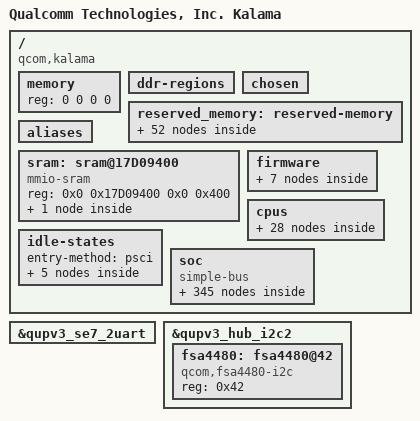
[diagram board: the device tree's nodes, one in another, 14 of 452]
#include <dt-bindings/interrupt-controller/arm-gic.h>
#include <dt-bindings/clock/qcom,camcc-kalama.h>
#include <dt-bindings/clock/qcom,dispcc-kalama.h>
#include <dt-bindings/clock/qcom,gcc-kalama.h>
#include <dt-bindings/clock/qcom,gpucc-kalama.h>
#include <dt-bindings/clock/qcom,rpmh.h>
#include <dt-bindings/clock/qcom,tcsrcc-kalama.h>
#include <dt-bindings/clock/qcom,videocc-kalama.h>
#include <dt-bindings/regulator/qcom,rpmh-regulator-levels.h>
#include <dt-bindings/interconnect/qcom,kalama.h>
#include <dt-bindings/soc/qcom,ipcc.h>
#include <dt-bindings/soc/qcom,rpmh-rsc.h>
#include <dt-bindings/interconnect/qcom,icc.h>
#include <dt-bindings/spmi/spmi.h>
#include <dt-bindings/power/qcom-aoss-qmp.h>
#include <dt-bindings/clock/qcom,aop-qmp.h>

/ {
	model = "Qualcomm Technologies, Inc. Kalama";
	compatible = "qcom,kalama";
	qcom,msm-id = <519 0x10000>;
	interrupt-parent = <&intc>;

	#address-cells = <2>;
	#size-cells = <2>;
	memory { device_type = "memory"; reg = <0 0 0 0>; };
	ddr-regions { };


	chosen: chosen {
			bootargs = "console=ttyMSM0,115200n8 loglevel=6 kpti=0 log_buf_len=256K kernel.panic_on_rcu_stall=1 service_locator.enable=1 msm_rtb.filter=0x237 rcupdate.rcu_expedited=1 rcu_nocbs=0-7 ftrace_dump_on_oops swiotlb=noforce loop.max_part=7 fw_devlink.strict=1 allow_mismatched_32bit_el0 cpufreq.default_governor=performance printk.console_no_auto_verbose=1 kasan=off sysctl.kernel.sched_pelt_multiplier=4 can.stats_timer=0 pcie_ports=compat irqaffinity=0-2 disable_dma32=on no-steal-acc cgroup.memory=nokmem,nosocket";
	};

	reserved_memory: reserved-memory { };

	aliases: aliases {
		serial0 = &qupv3_se7_2uart;
		hsuart0 = &qupv3_se14_4uart;
		sdhc2 = &sdhc_2;
		ufshc1 = &ufshc_mem; /* Embedded UFS Slot */
	};

	sram: sram@17D09400 {
		#address-cells = <2>;
		#size-cells = <2>;
		compatible = "mmio-sram";
		reg = <0x0 0x17D09400 0x0 0x400>;
		ranges = <0x0 0x0 0x0 0x17D09400 0x0 0x400>;

		cpu_scp_lpri: scmi-shmem@0 {
			compatible = "arm,scmi-shmem";
			reg = <0x0 0x0 0x0 0x400>;
		};
	};

	firmware: firmware { };

	cpus {
		#address-cells = <2>;
		#size-cells = <0>;

		CPU0: cpu@0 {
			device_type = "cpu";
			compatible = "qcom,kryo";
			reg = <0x0 0x0>;
			enable-method = "psci";
			cpu-idle-states = <&SILVER_OFF>;
			power-domains = <&CPU_PD0>;
			power-domain-names = "psci";
			cpu-release-addr = <0x0 0xE3940000>;
			qcom,freq-domain = <&cpufreq_hw 0>;
			capacity-dmips-mhz = <820>;
			dynamic-power-coefficient = <100>;
			#cooling-cells = <2>;
			next-level-cache = <&L2_0>;
			L2_0: l2-cache {
			      compatible = "arm,arch-cache";
			      cache-level = <2>;
			      next-level-cache = <&L3_0>;

				L3_0: l3-cache {
					compatible = "arm,arch-cache";
					cache-level = <3>;
				};
			};
		};

		CPU1: cpu@100 {
			device_type = "cpu";
			compatible = "qcom,kryo";
			reg = <0x0 0x100>;
			enable-method = "psci";
			cpu-idle-states = <&SILVER_OFF>;
			power-domains = <&CPU_PD1>;
			power-domain-names = "psci";
			cpu-release-addr = <0x0 0xE3940000>;
			qcom,freq-domain = <&cpufreq_hw 0>;
			capacity-dmips-mhz = <820>;
			dynamic-power-coefficient = <100>;
			#cooling-cells = <2>;
			next-level-cache = <&L2_1>;
			L2_1: l2-cache {
			      compatible = "arm,arch-cache";
			      cache-level = <2>;
			      next-level-cache = <&L3_0>;
			};
		};

		CPU2: cpu@200 {
			device_type = "cpu";
			compatible = "qcom,kryo";
			reg = <0x0 0x200>;
			enable-method = "psci";
			cpu-idle-states = <&SILVER_OFF>;
			power-domains = <&CPU_PD2>;
			power-domain-names = "psci";
			cpu-release-addr = <0x0 0xE3940000>;
			qcom,freq-domain = <&cpufreq_hw 0>;
			capacity-dmips-mhz = <820>;
			dynamic-power-coefficient = <100>;
			#cooling-cells = <2>;
			next-level-cache = <&L2_1>;
		};

		CPU3: cpu@300 {
			device_type = "cpu";
			compatible = "qcom,kryo";
			reg = <0x0 0x300>;
			enable-method = "psci";
			cpu-idle-states = <&GOLD_OFF>;
			power-domains = <&CPU_PD3>;
			power-domain-names = "psci";
			cpu-release-addr = <0x0 0xE3940000>;
			qcom,freq-domain = <&cpufreq_hw 1>;
			capacity-dmips-mhz = <1800>;
			dynamic-power-coefficient = <270>;
			#cooling-cells = <2>;
			next-level-cache = <&L2_3>;
			L2_3: l2-cache {
			      compatible = "arm,arch-cache";
			      cache-level = <2>;
			      next-level-cache = <&L3_0>;
			};
		};

		CPU4: cpu@400 {
			device_type = "cpu";
			compatible = "qcom,kryo";
			reg = <0x0 0x400>;
			enable-method = "psci";
			cpu-idle-states = <&GOLD_OFF>;
			power-domains = <&CPU_PD4>;
			power-domain-names = "psci";
			cpu-release-addr = <0x0 0xE3940000>;
			qcom,freq-domain = <&cpufreq_hw 1>;
			capacity-dmips-mhz = <1800>;
			dynamic-power-coefficient = <270>;
			#cooling-cells = <2>;
			next-level-cache = <&L2_4>;
			L2_4: l2-cache {
			      compatible = "arm,arch-cache";
			      cache-level = <2>;
			      next-level-cache = <&L3_0>;

			};
		};

		CPU5: cpu@500 {
			device_type = "cpu";
			compatible = "qcom,kryo";
			reg = <0x0 0x500>;
			enable-method = "psci";
			cpu-idle-states = <&GOLD_OFF>;
			power-domains = <&CPU_PD5>;
			power-domain-names = "psci";
			cpu-release-addr = <0x0 0xE3940000>;
			qcom,freq-domain = <&cpufreq_hw 1>;
			capacity-dmips-mhz = <1800>;
			dynamic-power-coefficient = <270>;
			#cooling-cells = <2>;
			next-level-cache = <&L2_5>;
			L2_5: l2-cache {
			      compatible = "arm,arch-cache";
			      cache-level = <2>;
			      next-level-cache = <&L3_0>;
			};
		};

		CPU6: cpu@600 {
			device_type = "cpu";
			compatible = "qcom,kryo";
			reg = <0x0 0x600>;
			enable-method = "psci";
			cpu-idle-states = <&GOLD_OFF>;
			power-domains = <&CPU_PD6>;
			power-domain-names = "psci";
			cpu-release-addr = <0x0 0xE3940000>;
			qcom,freq-domain = <&cpufreq_hw 1>;
			capacity-dmips-mhz = <1800>;
			dynamic-power-coefficient = <270>;
			#cooling-cells = <2>;
			next-level-cache = <&L2_6>;
			L2_6: l2-cache {
			      compatible = "arm,arch-cache";
			      cache-level = <2>;
			      next-level-cache = <&L3_0>;
			};
		};

		CPU7: cpu@700 {
			device_type = "cpu";
			compatible = "qcom,kryo";
			reg = <0x0 0x700>;
			enable-method = "psci";
			cpu-idle-states = <&GOLD_PLUS_OFF>;
			power-domains = <&CPU_PD7>;
			power-domain-names = "psci";
			cpu-release-addr = <0x0 0xE3940000>;
			qcom,freq-domain = <&cpufreq_hw 2>;
			capacity-dmips-mhz = <1894>;
			dynamic-power-coefficient = <588>;
			#cooling-cells = <2>;
			next-level-cache = <&L2_7>;
			L2_7: l2-cache {
			      compatible = "arm,arch-cache";
			      cache-level = <2>;
			      next-level-cache = <&L3_0>;
			};
		};

		cpu-map {
			cluster0 {
				core0 {
					cpu = <&CPU0>;
				};

				core1 {
					cpu = <&CPU1>;
				};

				core2 {
					cpu = <&CPU2>;
				};
			};

			cluster1 {
				core0 {
					cpu = <&CPU3>;
				};

				core1 {
					cpu = <&CPU4>;
				};

				core2 {
					cpu = <&CPU5>;
				};

				core3 {
					cpu = <&CPU6>;
				};
			};

			cluster2 {
				core0 {
					cpu = <&CPU7>;
				};
			};
		};
	};

	idle-states {
		entry-method = "psci";

		SILVER_OFF: silver-c4 {  /* C4 */
			compatible = "arm,idle-state";
			idle-state-name = "rail-pc";
			entry-latency-us = <550>;
			exit-latency-us = <750>;
			min-residency-us = <6700>;
			arm,psci-suspend-param = <0x40000004>;
			local-timer-stop;
		};

		GOLD_OFF: gold-c4 {  /* C4 */
			compatible = "arm,idle-state";
			idle-state-name = "rail-pc";
			entry-latency-us = <600>;
			exit-latency-us = <1300>;
			min-residency-us = <8136>;
			arm,psci-suspend-param = <0x40000004>;
			local-timer-stop;
		};

		GOLD_PLUS_OFF: gold-plus-c4 {  /* C4 */
			compatible = "arm,idle-state";
			idle-state-name = "rail-pc";
			entry-latency-us = <500>;
			exit-latency-us = <1350>;
			min-residency-us = <7480>;
			arm,psci-suspend-param = <0x40000004>;
			local-timer-stop;
		};

		CLUSTER_PWR_DN: cluster-d4 { /* D4 */
			compatible = "domain-idle-state";
			idle-state-name = "l3-off";
			entry-latency-us = <750>;
			exit-latency-us = <2350>;
			min-residency-us = <9144>;
			arm,psci-suspend-param = <0x41000044>;
		};

		APSS_OFF: cluster-e3 { /* E3 */
			compatible = "domain-idle-state";
			idle-state-name = "llcc-off";
			entry-latency-us = <2800>;
			exit-latency-us = <4400>;
			min-residency-us = <10150>;
			arm,psci-suspend-param = <0x4100c344>;
		};
	};


	soc: soc { };
};

&reserved_memory {
	#address-cells = <2>;
	#size-cells = <2>;
	ranges;

	gunyah_hyp_mem: gunyah_hyp_region@80000000 {
		no-map;
		reg = <0x0 0x80000000 0x0 0xa00000>;
	};

	cpusys_vm_mem: cpusys_vm_region@80a00000 {
		no-map;
		reg = <0x0 0x80a00000 0x0 0x400000>;
	};

	/*
	 * hyp_tags_mem & hyp_tags_reserved_mem not passed to linux
	 * as valid memory. Size of these regions varies based on
	 * bootloader policy.
	 */

	/* merged xbl_dt_log, xbl_ramdump, aop_image */
	xbl_dt_log_merged_mem: xbl_dt_log_merged@81a00000 {
		no-map;
		reg = <0x0 0x81a00000 0x0 0x260000>;
	};

	aop_cmd_db_mem: aop_cmd_db_region@81c60000 {
		compatible = "qcom,cmd-db";
		no-map;
		reg = <0x0 0x81c60000 0x0 0x20000>;
	};

	/* merged aop_config, tme_crash_dump, tme_log, uefi_log */
	aop_config_merged_mem: aop_config_merged_region@81c80000 {
		no-map;
		reg = <0x0 0x81c80000 0x0 0x74000>;
	};

	/* secdata region can be reused by apps */

	smem_mem: smem_region@81d00000 {
		no-map;
		reg = <0x0 0x81d00000 0x0 0x200000>;
	};

	adsp_mhi_mem: adsp_mhi_region@81f00000 {
		no-map;
		reg = <0x0 0x81f00000 0x0 0x20000>;
	};

	global_sync_mem: global_sync_region@82600000 {
		no-map;
		reg = <0x0 0x82600000 0x0 0x100000>;
	};

	tz_stat_mem: tz_stat_region@82700000 {
		no-map;
		reg = <0x0 0x82700000 0x0 0x100000>;
	};

	mpss_mem: mpss_region@89800000 {
		no-map;
		reg = <0x0 0x8a800000 0x0 0x10800000>;
	};

	q6_mpss_dtb_mem: q6_mpss_dtb_region@9b000000 {
		no-map;
		reg = <0x0 0x9b000000 0x0 0x80000>;
	};

	ipa_fw_mem: ipa_fw_region@9b080000 {
		no-map;
		reg = <0x0 0x9b080000 0x0 0x10000>;
	};

	ipa_gsi_mem: ipa_gsi_region@9b090000 {
		no-map;
		reg = <0x0 0x9b090000 0x0 0xa000>;
	};

	gpu_micro_code_mem: gpu_micro_code_region@9b09a000 {
		no-map;
		reg = <0x0 0x9b09a000 0x0 0x2000>;
	};

	spss_region_mem: spss_region_region@9b100000 {
		no-map;
		reg = <0x0 0x9b100000 0x0 0x180000>;
	};

	/* First part of the "SPU secure shared memory" region */
	spu_tz_shared_mem: spu_tz_shared_mem@9b280000 {
		no-map;
		reg = <0x0 0x9b280000 0x0 0x60000>;
	};

	/* Second part of the "SPU secure shared memory" region */
	spu_modem_shared_mem: spu_modem_shared_mem@9b2e0000 {
		no-map;
		reg = <0x0 0x9b2e0000 0x0 0x20000>;
	};

	camera_mem: camera_region@9b300000 {
		no-map;
		reg = <0x0 0x9b300000 0x0 0x800000>;
	};

	video_mem: video_region@9bb00000 {
		no-map;
		reg = <0x0 0x9bb00000 0x0 0x700000>;
	};

	cvp_mem: cvp_region@9c200000 {
		no-map;
		reg = <0x0 0x9c200000 0x0 0x700000>;
	};

	cdsp_mem: cdsp_region@9c900000 {
		no-map;
		reg = <0x0 0x9c900000 0x0 0x2000000>;
	};

	q6_cdsp_dtb_mem: q6_cdsp_dtb_region@9e900000 {
		no-map;
		reg = <0x0 0x9e900000 0x0 0x80000>;
	};

	q6_adsp_dtb_mem: q6_adsp_dtb_region@9e980000 {
		no-map;
		reg = <0x0 0x9e980000 0x0 0x80000>;
	};

	adspslpi_mem: adspslpi_region@9ea00000 {
		no-map;
		reg = <0x0 0x9ea00000 0x0 0x4080000>;
	};

	/* uefi region can be reused by apps */

	/* Linux kernel image is loaded at 0xa8000000 */

	mpss_dsm_mem: mpss_dsm_region@d4d00000 {
		no-map;
		reg = <0x0 0xd4d00000 0x0 0x3300000>;
	};

	/*
	 * tz_reserved_mem not passed to linux as valid memory. Size
	 * varies based on bootloader policy.
	 */

	xbl_sc_mem: xbl_sc_region@d8100000 {
		no-map;
		reg = <0x0 0xd8100000 0x0 0x40000>;
	};

	cpucp_fw_mem: cpucp_fw_region@d8140000 {
		no-map;
		reg = <0x0 0xd8140000 0x0 0x1c0000>;
	};

	qtee_mem: qtee_region@d8300000 {
		no-map;
		reg = <0x0 0xd8300000 0x0 0x500000>;
	};

	/*
	 * ta_mem & tz_tags_mem not passed to linux as valid memory. Size
	 * varies based on bootloader policy.
	 */

	hwfence_shbuf: hwfence-shmem {
		no-map;
		reg = <0x0 0xe6440000 0x0 0x2dd000>;
	};

	trust_ui_vm_mem: trust_ui_vm_region@f3800000 {
		no-map;
		reg = <0x0 0xf3800000 0x0 0x40ee000>;
	};

	trust_ui_vm_dump: trust_ui_vm_dump@0xf78ee000 {
		no-map;
		reg = <0x0 0xf78ee000 0x0 0x1000>;
	};

	trust_ui_vm_qrtr: trust_ui_vm_qrtr@0xf78ef000 {
		no-map;
		reg = <0x0 0xf78ef000 0x0 0x9000>;
	};

	trust_ui_vm_vblk0_ring: trust_ui_vm_vblk0_ring@0xf78f8000 {
		no-map;
		reg = <0x0 0xf78f8000 0x0 0x4000>;
		gunyah-label = <0x11>;					//for persist.img
	};

	trust_ui_vm_vblk1_ring: trust_ui_vm_vblk1_ring@0xf78fc000 {
		no-map;
		reg = <0x0 0xf78fc000 0x0 0x4000>;
		gunyah-label = <0x10>;					//for system.img
	};

	trust_ui_vm_swiotlb: trust_ui_vm_swiotlb@0xf7900000 {
		no-map;
		reg = <0x0 0xf7900000 0x0 0x100000>;
		gunyah-label = <0x12>;
	};

	llcc_lpi_mem: llcc_lpi_region@ff800000 {
		no-map;
		reg = <0x0 0xff800000 0x0 0x400000>;
	};

	va_md_mem: va_md_mem_region {
		compatible = "shared-dma-pool";
		alloc-ranges = <0x0 0x00000000 0x0 0xffffffff>;
		reusable;
		size = <0 0x1000000>;
	};

	sp_mem: sp_region {  /* SPSS-HLOS ION shared mem */
		compatible = "shared-dma-pool";
		alloc-ranges = <0x0 0x00000000 0x0 0xffffffff>;
		reusable;
		alignment = <0x0 0x400000>;
		size = <0x0 0x1000000>;
	};

	cdsp_eva_mem: cdsp_eva_region {
		compatible = "shared-dma-pool";
		alloc-ranges = <0x0 0x00000000 0x0 0xffffffff>;
		reusable;
		alignment = <0x0 0x400000>;
		size = <0x0 0x400000>;
	};

	adsp_mem_heap: adsp_heap_region {
		compatible = "shared-dma-pool";
		alloc-ranges = <0x0 0x00000000 0x0 0xffffffff>;
		reusable;
		alignment = <0x0 0x400000>;
		size = <0x0 0xC00000>;
	};

	user_contig_mem: user_contig_region {
		compatible = "shared-dma-pool";
		alloc-ranges = <0x0 0x00000000 0x0 0xffffffff>;
		reusable;
		alignment = <0x0 0x400000>;
		size = <0x0 0x1000000>;
	};

	qseecom_mem: qseecom_region {
		compatible = "shared-dma-pool";
		alloc-ranges = <0x0 0x00000000 0x0 0xffffffff>;
		reusable;
		alignment = <0x0 0x400000>;
		size = <0x0 0x1400000>;
	};

	cdsp_secure_heap: secure_cdsp_region { /* Secure DSP */
		compatible = "shared-dma-pool";
		alloc-ranges = <0x0 0x00000000 0x0 0xffffffff>;
		reusable;
		alignment = <0x0 0x400000>;
		size = <0x0 0x4800000>;
	};

	non_secure_display_memory: non_secure_display_region {
		compatible = "shared-dma-pool";
		reusable;
		alloc-ranges = <0x0 0x00000000 0x0 0xffffffff>;
		size = <0x0 0xa400000>;
		alignment = <0x0 0x400000>;
	};

	demura_heap_memory: demura_heap_region {
		compatible = "shared-dma-pool";
		reusable;
		alloc-ranges = <0x1 0x00000000 0xfffffffe 0xffffffff>;
		size = <0x0 0x2800000>;
		alignment = <0x0 0x400000>;
	};

	qseecom_ta_mem: qseecom_ta_region {
		compatible = "shared-dma-pool";
		alloc-ranges = <0x0 0x00000000 0x0 0xffffffff>;
		reusable;
		alignment = <0x0 0x400000>;
		size = <0x0 0x1000000>;
	};

	/* global autoconfigured region for contiguous allocations */
	system_cma: linux,cma {
		compatible = "shared-dma-pool";
		alloc-ranges = <0x0 0x00000000 0x0 0xffffffff>;
		reusable;
		alignment = <0x0 0x400000>;
		size = <0x0 0x2000000>;
		linux,cma-default;
	};

	kinfo_mem: debug_kinfo_region {
		alloc-ranges = <0x0 0x00000000 0xffffffff 0xffffffff>;
		size = <0x0 0x1000>;
		no-map;
	};

	debug_region: debug_region@ffc00000 {
		compatible = "removed-dma-pool", "qcom,debug_memory";
		no-map;
		reg = <0 0xffc00000 0 0xc0000>;
		label = "debug_mem";
	};

	last_log_region: last_log_region@ffcc0000 {
		compatible = "removed-dma-pool", "qcom,last_log_memory";
		no-map;
		reg = <0 0xffcc0000 0 0x40000>;
		label = "last_log";
		phandle = "log";
	};

	ramoops_mem: ramoops_region@ffd00000 {
		compatible = "removed-dma-pool", "ramoops";
		reg = <0 0xffd00000 0 0xc0000>;
		record-size = <0x1000>;
		console-size = <0x40000>;
		pmsg-size = <0x40000>;
		ftrace-size = <0x0>;
	};

	rdtag_store_region: rdtag_store_region@ffdc0000 {
		compatible = "removed-dma-pool", "rdtag_store_region";
		no-map;
		reg = <0 0xffdc0000 0 0x40000>;
		label = "rdtag_store_region";
	};
};

&soc {
	#address-cells = <1>;
	#size-cells = <1>;
	ranges = <0 0 0 0xffffffff>;
	compatible = "simple-bus";

	dsi_pll_codes {
	};

	psci {
		compatible = "arm,psci-1.0";
		method = "smc";

		CPU_PD0: cpu-pd0 {
			#power-domain-cells = <0>;
			power-domains = <&CLUSTER_PD>;
		};

		CPU_PD1: cpu-pd1 {
			#power-domain-cells = <0>;
			power-domains = <&CLUSTER_PD>;
		};

		CPU_PD2: cpu-pd2 {
			#power-domain-cells = <0>;
			power-domains = <&CLUSTER_PD>;
		};

		CPU_PD3: cpu-pd3 {
			#power-domain-cells = <0>;
			power-domains = <&CLUSTER_PD>;
		};

		CPU_PD4: cpu-pd4 {
			#power-domain-cells = <0>;
			power-domains = <&CLUSTER_PD>;
		};

		CPU_PD5: cpu-pd5 {
			#power-domain-cells = <0>;
			power-domains = <&CLUSTER_PD>;
		};

		CPU_PD6: cpu-pd6 {
			#power-domain-cells = <0>;
			power-domains = <&CLUSTER_PD>;
		};

		CPU_PD7: cpu-pd7 {
			#power-domain-cells = <0>;
			power-domains = <&CLUSTER_PD>;
		};

		CLUSTER_PD: cluster-pd {
			#power-domain-cells = <0>;
			domain-idle-states = <&CLUSTER_PWR_DN &APSS_OFF>;
		};
	};

	slimbam: bamdma@6C04000 {
		compatible = "qcom,bam-v1.7.0";
		qcom,controlled-remotely;
		reg = <0x6C04000 0x20000>, <0x6C8B000 0x1000>;
		reg-names = "bam", "bam_remote_mem";
		num-channels  = <31>;
		interrupts = <0 164 IRQ_TYPE_LEVEL_HIGH>;
		#dma-cells = <1>;
		qcom,ee = <1>;
		qcom,num-ees = <2>;
	};

	slim_msm: slim@6C40000 {
		compatible = "qcom,slim-ngd-v1.5.0";
		reg = <0x6C40000 0x2C000>, <0x6C8A000 0x1000>;
		reg-names = "ctrl", "slimbus_remote_mem";
		interrupts = <0 163 IRQ_TYPE_LEVEL_HIGH>;
		qcom,apps-ch-pipes = <0x0>;
		qcom,ea-pc = <0x430>;
		dmas = <&slimbam 3>, <&slimbam 4>;
		dma-names = "rx", "tx";
		#address-cells = <1>;
		#size-cells = <0>;
		status = "disabled";
	};


	intc: interrupt-controller@17100000 {
		compatible = "arm,gic-v3";
		#interrupt-cells = <3>;
		interrupt-controller;
		ranges;
		#redistributor-regions = <1>;
		redistributor-stride = <0x0 0x40000>;
		reg = <0x17100000 0x10000>,	/* GICD */
		      <0x17180000 0x200000>;	/* GICR * 8 */
		interrupts = <GIC_PPI 9 IRQ_TYPE_LEVEL_HIGH>;

		#address-cells = <1>;
		#size-cells = <1>;
		gic_its: msi-controller@17140000 {
			compatible = "arm,gic-v3-its";
			msi-controller;
			#msi-cells = <1>;
			reg = <0x17140000 0x20000>;
		};
	};

	apps_rsc: rsc@17a00000 {
		label = "apps_rsc";
		compatible = "qcom,rpmh-rsc";
		reg = <0x17a00000 0x10000>,
		      <0x17a10000 0x10000>,
		      <0x17a20000 0x10000>;
		reg-names = "drv-0", "drv-1", "drv-2";
		qcom,drv-count = <3>;
		interrupts = <GIC_SPI 3 IRQ_TYPE_LEVEL_HIGH>,
			     <GIC_SPI 4 IRQ_TYPE_LEVEL_HIGH>,
			     <GIC_SPI 5 IRQ_TYPE_LEVEL_HIGH>;
		power-domains = <&CLUSTER_PD>;

		apps_rsc_drv2: drv@2 {
			qcom,drv-id = <2>;
			qcom,tcs-offset = <0xd00>;
			channel@0 {
				qcom,tcs-config = <ACTIVE_TCS    3>,
						  <SLEEP_TCS     2>,
						  <WAKE_TCS      2>,
						  <CONTROL_TCS   0>,
						  <FAST_PATH_TCS 1>;
			};

			apps_bcm_voter: bcm_voter {
				compatible = "qcom,bcm-voter";
			};

			rpmhcc: clock-controller {
				compatible = "qcom,kalama-rpmh-clk";
				#clock-cells = <1>;
			};

			dcvs_fp: qcom,dcvs-fp {
				compatible = "qcom,dcvs-fp";
				qcom,ddr-bcm-name = "MC4";
				qcom,llcc-bcm-name = "SH5";
			};
		};
	};

	arch_timer: timer {
		compatible = "arm,armv8-timer";
		interrupts = <GIC_PPI 13 (GIC_CPU_MASK_SIMPLE(8) | IRQ_TYPE_LEVEL_LOW)>,
			     <GIC_PPI 14 (GIC_CPU_MASK_SIMPLE(8) | IRQ_TYPE_LEVEL_LOW)>,
			     <GIC_PPI 11 (GIC_CPU_MASK_SIMPLE(8) | IRQ_TYPE_LEVEL_LOW)>,
			     <GIC_PPI 12 (GIC_CPU_MASK_SIMPLE(8) | IRQ_TYPE_LEVEL_LOW)>;
		clock-frequency = <19200000>;
	};

	cam_rsc: rsc@add9000 {
		label = "cam_rsc";
		compatible = "qcom,rpmh-rsc";
		reg = <0xadd9000 0x1000>,
		      <0xadda000 0x1000>,
		      <0xaddb000 0x1000>;
		reg-names = "drv-0", "drv-1", "drv-2";
		qcom,drv-count = <3>;
		qcom,hw-channel;
		interrupts = <GIC_SPI 368 IRQ_TYPE_LEVEL_HIGH>,
			     <GIC_SPI 369 IRQ_TYPE_LEVEL_HIGH>,
			     <GIC_SPI 370 IRQ_TYPE_LEVEL_HIGH>;
		clocks = <&camcc CAM_CC_DRV_AHB_CLK>;

		cam_rsc_drv0: drv@0 {
			qcom,drv-id = <0>;
			qcom,tcs-offset = <0x520>;
			channel@0 {
				qcom,tcs-config = <ACTIVE_TCS    0>,
						  <WAKE_TCS      1>,
						  <SLEEP_TCS     1>,
						  <CONTROL_TCS   0>,
						  <FAST_PATH_TCS 0>;
			};

			channel@1 {
				qcom,tcs-config = <ACTIVE_TCS    0>,
						  <WAKE_TCS      1>,
						  <SLEEP_TCS     1>,
						  <CONTROL_TCS   0>,
						  <FAST_PATH_TCS 0>;
			};

			cam_bcm_voter0: bcm_voter {
				compatible = "qcom,bcm-voter";
			};
		};

		cam_rsc_drv1: drv@1 {
			qcom,drv-id = <1>;
			qcom,tcs-offset = <0x520>;
			channel@0 {
				qcom,tcs-config = <ACTIVE_TCS    0>,
						  <WAKE_TCS      1>,
						  <SLEEP_TCS     1>,
						  <CONTROL_TCS   0>,
						  <FAST_PATH_TCS 0>;
			};

			channel@1 {
				qcom,tcs-config = <ACTIVE_TCS    0>,
						  <WAKE_TCS      1>,
						  <SLEEP_TCS     1>,
						  <CONTROL_TCS   0>,
						  <FAST_PATH_TCS 0>;
			};

			cam_bcm_voter1: bcm_voter {
				compatible = "qcom,bcm-voter";
			};
		};

		cam_rsc_drv2: drv@2 {
			qcom,drv-id = <2>;
			qcom,tcs-offset = <0x520>;
			channel@0 {
				qcom,tcs-config = <ACTIVE_TCS    0>,
						  <WAKE_TCS      1>,
						  <SLEEP_TCS     1>,
						  <CONTROL_TCS   0>,
						  <FAST_PATH_TCS 0>;
			};

			channel@1 {
				qcom,tcs-config = <ACTIVE_TCS    0>,
						  <WAKE_TCS      1>,
						  <SLEEP_TCS     1>,
						  <CONTROL_TCS   0>,
						  <FAST_PATH_TCS 0>;
			};

			cam_bcm_voter2: bcm_voter {
				compatible = "qcom,bcm-voter";
			};
		};
	};

	disp_rsc: rsc@af20000 {
		label = "disp_rsc";
		compatible = "qcom,rpmh-rsc";
		reg = <0xaf20000 0x10000>;
		reg-names = "drv-0";
		qcom,drv-count = <1>;
		interrupts = <GIC_SPI 129 IRQ_TYPE_LEVEL_HIGH>;
		clocks = <&dispcc DISP_CC_MDSS_RSCC_AHB_CLK>;

		disp_rsc_drv0: drv@0 {
			qcom,drv-id = <0>;
			qcom,tcs-offset = <0x1c00>;
			channel@0 {
				qcom,tcs-config = <ACTIVE_TCS    0>,
						  <SLEEP_TCS     1>,
						  <WAKE_TCS      1>,
						  <CONTROL_TCS   0>,
						  <FAST_PATH_TCS 0>;
			};

			disp_bcm_voter: bcm_voter {
				compatible = "qcom,bcm-voter";
				qcom,tcs-wait = <QCOM_ICC_TAG_AMC>;
			};
		};
	};

	memtimer: timer@17420000 {
		#address-cells = <1>;
		#size-cells = <1>;
		ranges;
		compatible = "arm,armv7-timer-mem";
		reg = <0x17420000 0x1000>;
		clock-frequency = <19200000>;

		frame@17421000 {
			frame-number = <0>;
			interrupts = <GIC_SPI 8 IRQ_TYPE_LEVEL_HIGH>,
				     <GIC_SPI 6 IRQ_TYPE_LEVEL_HIGH>;
			reg = <0x17421000 0x1000>,
			      <0x17422000 0x1000>;
		};

		frame@17423000 {
			frame-number = <1>;
			interrupts = <GIC_SPI 9 IRQ_TYPE_LEVEL_HIGH>;
			reg = <0x17423000 0x1000>;
			status = "disabled";
		};

		frame@17425000 {
			frame-number = <2>;
			interrupts = <GIC_SPI 10 IRQ_TYPE_LEVEL_HIGH>;
			reg = <0x17425000 0x1000>;
			status = "disabled";
		};

		frame@17427000 {
			frame-number = <3>;
			interrupts = <GIC_SPI 11 IRQ_TYPE_LEVEL_HIGH>;
			reg = <0x17427000 0x1000>;
			status = "disabled";
		};

		frame@17429000 {
			frame-number = <4>;
			interrupts = <GIC_SPI 12 IRQ_TYPE_LEVEL_HIGH>;
			reg = <0x17429000 0x1000>;
			status = "disabled";
		};

		frame@1742b000 {
			frame-number = <5>;
			interrupts = <GIC_SPI 13 IRQ_TYPE_LEVEL_HIGH>;
			reg = <0x1742b000 0x1000>;
			status = "disabled";
		};

		frame@1742d000 {
			frame-number = <6>;
			interrupts = <GIC_SPI 14 IRQ_TYPE_LEVEL_HIGH>;
			reg = <0x1742d000 0x1000>;
			status = "disabled";
		};
	};

	rimps: qcom,rimps@17400000 {
		#address-cells = <2>;
		#size-cells = <2>;
		compatible = "qcom,rimps";
		reg =   <0x17400000 0x10>,
			<0x17d90000 0x2000>;
		#mbox-cells = <1>;
		interrupts = <GIC_SPI 62 IRQ_TYPE_LEVEL_HIGH>;
	};

	scmi: qcom,scmi {
		#address-cells = <1>;
		#size-cells = <0>;
		compatible = "arm,scmi";
		mboxes = <&rimps 0>;
		mbox-names = "tx";
		shmem = <&cpu_scp_lpri>;

		scmi_memlat: protocol@80 {
			reg = <0x80>;
			#clock-cells = <1>;
		};

		scmi_plh: protocol@81 {
			reg = <0x81>;
			#clock-cells = <1>;
		};

		scmi_pmu: protocol@86 {
			reg = <0x86>;
			#clock-cells = <1>;
		};

		scmi_c1dcvs: protocol@87 {
			reg = <0x87>;
			#clock-cells = <1>;
		};

	};

	rimps_log: qcom,rimps_log@d8140000 {
		compatible = "qcom,rimps-log";
		reg = <0xd8140000 0x10000>, <0xd8150000 0x10000>;
		mboxes = <&rimps 1>;
	};

	cpu_pmu: cpu-pmu {
		compatible = "arm,armv8-pmuv3";
		interrupts = <GIC_PPI 7 IRQ_TYPE_LEVEL_HIGH>;
	};

	dmesg-dump {
		compatible = "qcom,dmesg-dump";
		qcom,primary-vm;
		gunyah-label = <7>;
		peer-name = <2>;
		shared-buffer = <&trust_ui_vm_dump>;
	};

	clk_virt: interconnect@0 {
		compatible = "qcom,kalama-clk_virt";
		#interconnect-cells = <1>;
		qcom,bcm-voter-names = "hlos";
		qcom,bcm-voters = <&apps_bcm_voter>;
	};

	mc_virt: interconnect@1 {
		compatible = "qcom,kalama-mc_virt";
		#interconnect-cells = <1>;
		qcom,bcm-voter-names = "hlos", "disp", "cam_ife_0", "cam_ife_1", "cam_ife_2";
		qcom,bcm-voters = <&apps_bcm_voter>,
				  <&disp_bcm_voter>,
				  <&cam_bcm_voter0>,
				  <&cam_bcm_voter1>,
				  <&cam_bcm_voter2>;
	};

	config_noc: interconnect@1600000 {
		compatible = "qcom,kalama-cnoc_cfg";
		reg = <0x1600000 0x6200>;
		#interconnect-cells = <1>;
		qcom,bcm-voter-names = "hlos";
		qcom,bcm-voters = <&apps_bcm_voter>;
	};

	cnoc_main: interconnect@1500000 {
		compatible = "qcom,kalama-cnoc_main";
		reg = <0x1500000 0x13080>;
		#interconnect-cells = <1>;
		qcom,bcm-voter-names = "hlos";
		qcom,bcm-voters = <&apps_bcm_voter>;
	};

	system_noc: interconnect@1680000 {
		compatible = "qcom,kalama-system_noc";
		reg = <0x1680000 0x1D080>;
		#interconnect-cells = <1>;
		qcom,bcm-voter-names = "hlos";
		qcom,bcm-voters = <&apps_bcm_voter>;
	};

	pcie_noc: interconnect@16c0000 {
		compatible = "qcom,kalama-pcie_anoc";
		reg = <0x16c0000 0x12200>;
		#interconnect-cells = <1>;
		clocks = <&gcc GCC_AGGRE_NOC_PCIE_AXI_CLK>,
			 <&gcc GCC_CFG_NOC_PCIE_ANOC_AHB_CLK>;
		qcom,bcm-voter-names = "hlos";
		qcom,bcm-voters = <&apps_bcm_voter>;
	};

	aggre1_noc: interconnect@16e0000 {
		compatible = "qcom,kalama-aggre1_noc";
		reg = <0x16E0000 0x14400>;
		#interconnect-cells = <1>;
		clocks =
			<&gcc GCC_AGGRE_UFS_PHY_AXI_CLK>,
			<&gcc GCC_AGGRE_USB3_PRIM_AXI_CLK>;
		qcom,bcm-voter-names = "hlos";
		qcom,bcm-voters = <&apps_bcm_voter>;
	};

	aggre2_noc: interconnect@1700000 {
		compatible = "qcom,kalama-aggre2_noc";
		reg = <0x1700000 0x1E400>;
		#interconnect-cells = <1>;
		qcom,bcm-voter-names = "hlos";
		qcom,bcm-voters = <&apps_bcm_voter>;
		clocks = <&rpmhcc RPMH_IPA_CLK>;
	};

	mmss_noc: interconnect@1780000 {
		compatible = "qcom,kalama-mmss_noc";
		reg = <0x1780000 0x5B800>;
		#interconnect-cells = <1>;
		qcom,bcm-voter-names = "hlos", "disp", "cam_ife_0", "cam_ife_1", "cam_ife_2";
		qcom,bcm-voters = <&apps_bcm_voter>,
				  <&disp_bcm_voter>,
				  <&cam_bcm_voter0>,
				  <&cam_bcm_voter1>,
				  <&cam_bcm_voter2>;
	};

	gem_noc: interconnect@24100000 {
		compatible = "qcom,kalama-gem_noc";
		reg = <0x24100000 0xBB800>;
		#interconnect-cells = <1>;
		qcom,bcm-voter-names = "hlos", "disp", "cam_ife_0", "cam_ife_1", "cam_ife_2";
		qcom,bcm-voters = <&apps_bcm_voter>,
				  <&disp_bcm_voter>,
				  <&cam_bcm_voter0>,
				  <&cam_bcm_voter1>,
				  <&cam_bcm_voter2>;
	};

	nsp_noc: interconnect@320c0000 {
		compatible = "qcom,kalama-nsp_noc";
		reg = <0x320C0000 0xE080>;
		#interconnect-cells = <1>;
		qcom,bcm-voter-names = "hlos";
		qcom,bcm-voters = <&apps_bcm_voter>;
	};

	lpass_ag_noc: interconnect@7e40000 {
		compatible = "qcom,kalama-lpass_ag_noc";
		reg = <0x7e40000 0xE080>;
		#interconnect-cells = <1>;
		qcom,bcm-voter-names = "hlos";
		qcom,bcm-voters = <&apps_bcm_voter>;
	};

	lpass_lpiaon_noc: interconnect@7400000 {
		compatible = "qcom,kalama-lpass_lpiaon_noc";
		reg = <0x7400000 0x19080>;
		#interconnect-cells = <1>;
		qcom,bcm-voter-names = "hlos";
		qcom,bcm-voters = <&apps_bcm_voter>;
	};

	lpass_lpicx_noc: interconnect@7430000 {
		compatible = "qcom,kalama-lpass_lpicx_noc";
		reg = <0x7430000 0x3A200>;
		#interconnect-cells = <1>;
		qcom,bcm-voter-names = "hlos";
		qcom,bcm-voters = <&apps_bcm_voter>;
	};

	pdc: interrupt-controller@b220000 {
		compatible = "qcom,kalama-pdc", "qcom,pdc";
		reg = <0xb220000 0x30000>, <0x174000f0 0x64>;
		qcom,pdc-ranges = <0 480 94>, <94 609 31>,
				  <125 63 1>, <126 716 12>,
				  <138 251 5>;
		#interrupt-cells = <2>;
		interrupt-parent = <&intc>;
		interrupt-controller;
	};

	vendor_hooks: qcom,cpu-vendor-hooks {
		compatible = "qcom,cpu-vendor-hooks";
	};

	logbuf: qcom,logbuf-vendor-hooks {
		compatible = "qcom,logbuf-vendor-hooks";
	};

	qcom,sps {
		compatible = "qcom,msm-sps-4k";
		qcom,pipe-attr-ee;
	};

	qcom_qseecom: qseecom@c1700000 {
		compatible = "qcom,qseecom";
		memory-region = <&qseecom_mem>;
		qseecom_mem = <&qseecom_mem>;
		qseecom_ta_mem = <&qseecom_ta_mem>;
		user_contig_mem = <&user_contig_mem>;
		qcom,hlos-num-ce-hw-instances = <1>;
		qcom,hlos-ce-hw-instance = <0>;
		qcom,qsee-ce-hw-instance = <0>;
		qcom,disk-encrypt-pipe-pair = <2>;
		qcom,no-clock-support;
		qcom,appsbl-qseecom-support;
		qcom,commonlib64-loaded-by-uefi;
		qcom,qsee-reentrancy-support = <2>;
	};

	qcom_tzlog: tz-log@146AA720 {
		compatible = "qcom,tz-log";
		reg = <0x146AA720 0x3000>;
		qcom,hyplog-enabled;
		hyplog-address-offset = <0x410>;
		hyplog-size-offset = <0x414>;
	};

	qcom_cedev: qcedev@1de0000 {
		compatible = "qcom,qcedev";
		reg = <0x1de0000 0x20000>,
			<0x1dc4000 0x28000>;
		reg-names = "crypto-base","crypto-bam-base";
		interrupts = <GIC_SPI 272 IRQ_TYPE_LEVEL_HIGH>;
		qcom,bam-pipe-pair = <2>;
		qcom,offload-ops-support;
		qcom,bam-pipe-offload-cpb-hlos = <1>;
		qcom,bam-pipe-offload-hlos-cpb = <3>;
		qcom,bam-pipe-offload-hlos-hlos = <4>;
		qcom,ce-hw-instance = <0>;
		qcom,ce-device = <0>;
		qcom,ce-hw-shared;
		qcom,bam-ee = <0>;
		qcom,smmu-s1-enable;
		qcom,no-clock-support;
		interconnect-names = "data_path";
		interconnects = <&aggre2_noc MASTER_CRYPTO &mc_virt SLAVE_EBI1>;
		iommus = <&apps_smmu 0x0480 0x0>,
			<&apps_smmu 0x0481 0x0>;
		qcom,iommu-dma = "atomic";
		dma-coherent;

		qcom_cedev_ns_cb {
			compatible = "qcom,qcedev,context-bank";
			label = "ns_context";
			iommus = <&apps_smmu 0x0481 0x0>;
			dma-coherent;
		};

		qcom_cedev_s_cb {
			compatible = "qcom,qcedev,context-bank";
			label = "secure_context";
			iommus = <&apps_smmu 0x0483 0x0>;
			qcom,iommu-vmid = <0x9>;
			qcom,secure-context-bank;
			dma-coherent;
		};
	};

	qcom_rng: qrng@10c3000 {
		compatible = "qcom,msm-rng";
		reg = <0x10c3000 0x1000>;
		qcom,no-qrng-config;
		qcom,no-clock-support;
	};

	qcom,msm-imem@146aa000 {
		compatible = "qcom,msm-imem";
		reg = <0x146aa000 0x1000>;
		ranges = <0x0 0x146aa000 0x1000>;
		#address-cells = <1>;
		#size-cells = <1>;

		mem_dump_table@10 {
			compatible = "qcom,msm-imem-mem_dump_table";
			reg = <0x10 0x8>;
		};

		restart_reason@65c {
			compatible = "qcom,msm-imem-restart_reason";
			reg = <0x65c 0x4>;
		};

		dload_type@1c {
			compatible = "qcom,msm-imem-dload-type";
			reg = <0x1c 0x4>;
		};

		boot_stats@6b0 {
			compatible = "qcom,msm-imem-boot_stats";
			reg = <0x6b0 0x20>;
		};

		kaslr_offset@6d0 {
			compatible = "qcom,msm-imem-kaslr_offset";
			reg = <0x6d0 0xc>;
		};

		pil@94c {
			compatible = "qcom,pil-reloc-info";
			reg = <0x94c 0xc8>;
		};

		pil@6dc {
			compatible = "qcom,msm-imem-pil-disable-timeout";
			reg = <0x6dc 0x4>;
		};

		diag_dload@c8 {
			compatible = "qcom,msm-imem-diag-dload";
			reg = <0xc8 0xc8>;
		};
	};

	/* PIL spss node - for loading Secure Processor */
	spss_pas: remoteproc-spss@1880000 {
		compatible = "qcom,kalama-spss-pas";
		ranges;
		reg = <0x188101c 0x4>,
		      <0x1881024 0x4>,
		      <0x1881028 0x4>,
		      <0x188103c 0x4>,
		      <0x1881100 0x4>,
		      <0x1882014 0x4>;
		reg-names = "sp2soc_irq_status", "sp2soc_irq_clr", "sp2soc_irq_mask",
			    "rmb_err", "rmb_general_purpose", "rmb_err_spare2";
		interrupts = <0 352 1>;

		cx-supply = <&VDD_CX_LEVEL>;
		cx-uV-uA = <RPMH_REGULATOR_LEVEL_TURBO 100000>;

		clocks = <&rpmhcc RPMH_CXO_CLK>;
		clock-names = "xo";
		qcom,proxy-clock-names = "xo";
		status = "ok";

		memory-region = <&spss_region_mem>;
		qcom,spss-scsr-bits = <24 25>;
		qcom,extra-size = <4096>;

		interconnects = <&aggre2_noc MASTER_CRYPTO &mc_virt SLAVE_EBI1>;
		interconnect-names = "crypto_ddr";

		glink-edge {
			qcom,remote-pid = <8>;
			mboxes = <&ipcc_mproc IPCC_CLIENT_SPSS
				  IPCC_MPROC_SIGNAL_GLINK_QMP>;
			mbox-names = "spss_spss";
			interrupt-parent = <&ipcc_mproc>;
			interrupts = <IPCC_CLIENT_SPSS
				      IPCC_MPROC_SIGNAL_GLINK_QMP
				      IRQ_TYPE_EDGE_RISING>;

			reg = <0x1885008 0x8>,
			      <0x1885010 0x4>;
			reg-names = "qcom,spss-addr",
				    "qcom,spss-size";

			label = "spss";
			qcom,glink-label = "spss";
		};
	};

	qcom,spcom {
		compatible = "qcom,spcom";

		qcom,rproc-handle = <&spss_pas>;
		qcom,boot-enabled;
		/* predefined channels, remote side is server */
		qcom,spcom-ch-names = "sp_kernel", "sp_ssr";
		/* sp2soc rmb shared register physical address and bmsk */
		qcom,spcom-sp2soc-rmb-reg-addr = <0x01881020>;
		qcom,spcom-sp2soc-rmb-initdone-bit = <24>;
		qcom,spcom-sp2soc-rmb-pbldone-bit = <25>;
		/* soc2sp rmb shared register physical address */
		qcom,spcom-soc2sp-rmb-reg-addr = <0x01881030>;
		qcom,spcom-soc2sp-rmb-sp-ssr-bit = <0>;
		status = "ok";
	};

	spss_utils: qcom,spss_utils {
		compatible = "qcom,spss-utils";
		/* spss fuses physical address */
		qcom,rproc-handle = <&spss_pas>;
		qcom,spss-fuse1-addr = <0x221C8214>;
		qcom,spss-fuse1-bit = <8>;
		qcom,spss-fuse2-addr = <0x221C8214>;
		qcom,spss-fuse2-bit = <7>;
		qcom,spss-dev-firmware-name  = "spss1d.mdt";  /* 8 chars max */
		qcom,spss-test-firmware-name = "spss1t.mdt";  /* 8 chars max */
		qcom,spss-prod-firmware-name = "spss1p.mdt";  /* 8 chars max */
		qcom,spss-debug-reg-addr = <0x01886020>;
		qcom,spss-debug-reg-addr1 = <0x01888020>;
		qcom,spss-debug-reg-addr3 = <0x0188C020>;
		qcom,spss-emul-type-reg-addr = <0x01fc8004>;
		pil-mem = <&spss_region_mem>;
		qcom,pil-size = <0x0F0000>; // padding to 960KB
		status = "ok";
	};

	qcom,msm-rtb {
		compatible = "qcom,msm-rtb";
		qcom,rtb-size = <0x100000>;
	};

	tlmm: pinctrl@f000000 {
		compatible = "qcom,kalama-pinctrl";
		reg = <0x0F000000 0x1000000>;
		interrupts = <GIC_SPI 208 IRQ_TYPE_LEVEL_HIGH>;
		gpio-controller;
		#gpio-cells = <2>;
		interrupt-controller;
		#interrupt-cells = <2>;
		wakeup-parent = <&pdc>;
		qcom,gpios-reserved = <32 33 34 35 36 37 38 39>;
	};

	dload_mode {
		compatible = "qcom,dload-mode";
	};

	microdump_modem {
		compatible = "qcom,microdump_modem";
	 };

	mini_dump_mode {
		compatible = "qcom,minidump";
		status = "ok";
	};

	va_mini_dump {
		compatible = "qcom,va-minidump";
		memory-region = <&va_md_mem>;
		status = "ok";
	};

	gic-interrupt-router {
		compatible = "qcom,gic-intr-routing";
		/* keep silver core only to avoid wakeup of gold cores */
		qcom,gic-class0-cpus = <0 1 2>;
		/* keep gold and gold+ cores in class1 */
		qcom,gic-class1-cpus = <3 4 5 6 7>;
	};

	qcom,secure-buffer {
		compatible = "qcom,secure-buffer";
		qcom,vmid-cp-camera-preview-ro;
	};

	qcom,mem-buf {
		compatible = "qcom,mem-buf";
		qcom,mem-buf-capabilities = "supplier";
		qcom,vmid = <3>;
	};

	qcom,mem-buf-msgq {
		compatible = "qcom,mem-buf-msgq";
	};

	qcom,memshare {
		compatible = "qcom,memshare";

		qcom,client_1 {
			compatible = "qcom,memshare-peripheral";
			qcom,peripheral-size = <0x0>;
			qcom,client-id = <0>;
			qcom,allocate-boot-time;
			label = "modem";
		};

		qcom,client_2 {
			compatible = "qcom,memshare-peripheral";
			qcom,peripheral-size = <0x0>;
			qcom,client-id = <2>;
			label = "modem";
		};

		qcom,client_3 {
			compatible = "qcom,memshare-peripheral";
			qcom,peripheral-size = <0x500000>;
			qcom,client-id = <1>;
			qcom,allocate-on-request;
			label = "modem";
		};
	};

	clocks {
		xo_board: xo_board {
			compatible = "fixed-clock";
			clock-frequency = <76800000>;
			clock-output-names = "xo_board";
			#clock-cells = <0>;
		};

		sleep_clk: sleep_clk {
			compatible = "fixed-clock";
			clock-frequency = <32000>;
			clock-output-names = "sleep_clk";
			#clock-cells = <0>;
		};
	};

	camcc: clock-controller@ade0000 {
		compatible = "qcom,kalama-camcc", "syscon";
		reg = <0xade0000 0x20000>;
		reg-name = "cc_base";
		vdd_mm-supply = <&VDD_MM_LEVEL>;
		vdd_mxa-supply = <&VDD_MXA_LEVEL>;
		vdd_mxc-supply = <&VDD_MXC_LEVEL>;
		clocks = <&rpmhcc RPMH_CXO_CLK>,
			 <&rpmhcc RPMH_CXO_CLK_A>,
			 <&sleep_clk>,
			 <&gcc GCC_CAMERA_AHB_CLK>;
		clock-names = "bi_tcxo",
			      "bi_tcxo_ao",
			      "sleep_clk",
			      "iface";
		#clock-cells = <1>;
		#reset-cells = <1>;
	};

	cpuss-sleep-stats@17800054 {
	      compatible = "qcom,cpuss-sleep-stats";
	      reg = <0x17800054 0x4>, <0x17810054 0x4>, <0x17820054 0x4>,
		    <0x17830054 0x4>, <0x17840054 0x4>, <0x17850054 0x4>,
		    <0x17860054 0x4>, <0x17870054 0x4>, <0x178a0098 0x4>,
		    <0x178c0000 0x10000>;
	      reg-names = "seq_lpm_cntr_cfg_cpu0", "seq_lpm_cntr_cfg_cpu1",
			  "seq_lpm_cntr_cfg_cpu2", "seq_lpm_cntr_cfg_cpu3",
			  "seq_lpm_cntr_cfg_cpu4", "seq_lpm_cntr_cfg_cpu5",
			  "seq_lpm_cntr_cfg_cpu6", "seq_lpm_cntr_cfg_cpu7",
			  "l3_seq_lpm_cntr_cfg", "apss_seq_mem_base";
	      num-cpus = <8>;
	};

	dispcc: clock-controller@af00000 {
		compatible = "qcom,kalama-dispcc", "syscon";
		reg = <0xaf00000 0x20000>;
		reg-name = "cc_base";
		vdd_mm-supply = <&VDD_MM_LEVEL>;
		vdd_mxa-supply = <&VDD_MXA_LEVEL>;
		clocks = <&rpmhcc RPMH_CXO_CLK>,
			 <&sleep_clk>,
			 <&gcc GCC_DISP_AHB_CLK>;
		clock-names = "bi_tcxo",
			      "sleep_clk",
			      "iface";
		#clock-cells = <1>;
		#reset-cells = <1>;
	};

	pcie_0_pipe_clk: pcie_0_pipe_clk {
		compatible = "fixed-clock";
		clock-frequency = <1000>;
		clock-output-names = "pcie_0_pipe_clk";
		#clock-cells = <0>;
	};

	pcie_1_phy_aux_clk: pcie_1_phy_aux_clk {
		compatible = "fixed-clock";
		clock-frequency = <1000>;
		clock-output-names = "pcie_1_phy_aux_clk";
		#clock-cells = <0>;
	};

	pcie_1_pipe_clk: pcie_1_pipe_clk {
		compatible = "fixed-clock";
		clock-frequency = <1000>;
		clock-output-names = "pcie_1_pipe_clk";
		#clock-cells = <0>;
	};

	ufs_phy_rx_symbol_0_clk: ufs_phy_rx_symbol_0_clk {
		compatible = "fixed-clock";
		clock-frequency = <1000>;
		clock-output-names = "ufs_phy_rx_symbol_0_clk";
		#clock-cells = <0>;
	};

	ufs_phy_rx_symbol_1_clk: ufs_phy_rx_symbol_1_clk {
		compatible = "fixed-clock";
		clock-frequency = <1000>;
		clock-output-names = "ufs_phy_rx_symbol_1_clk";
		#clock-cells = <0>;
	};

	ufs_phy_tx_symbol_0_clk: ufs_phy_tx_symbol_0_clk {
		compatible = "fixed-clock";
		clock-frequency = <1000>;
		clock-output-names = "ufs_phy_tx_symbol_0_clk";
		#clock-cells = <0>;
	};

	usb3_phy_wrapper_gcc_usb30_pipe_clk: usb3_phy_wrapper_gcc_usb30_pipe_clk {
		compatible = "fixed-clock";
		clock-frequency = <1000>;
		clock-output-names = "usb3_phy_wrapper_gcc_usb30_pipe_clk";
		#clock-cells = <0>;
	};

	gcc: clock-controller@100000 {
		compatible = "qcom,kalama-gcc", "syscon";
		reg = <0x100000 0x1f4200>;
		reg-name = "cc_base";
		vdd_cx-supply = <&VDD_CX_LEVEL>;
		vdd_mxa-supply = <&VDD_MXA_LEVEL>;
		clocks = <&rpmhcc RPMH_CXO_CLK>,
			 <&pcie_0_pipe_clk>,
			 <&pcie_1_phy_aux_clk>,
			 <&pcie_1_pipe_clk>,
			 <&sleep_clk>,
			 <&ufs_phy_rx_symbol_0_clk>,
			 <&ufs_phy_rx_symbol_1_clk>,
			 <&ufs_phy_tx_symbol_0_clk>,
			 <&usb3_phy_wrapper_gcc_usb30_pipe_clk>;
		clock-names = "bi_tcxo",
			      "pcie_0_pipe_clk",
			      "pcie_1_phy_aux_clk",
			      "pcie_1_pipe_clk",
			      "sleep_clk",
			      "ufs_phy_rx_symbol_0_clk",
			      "ufs_phy_rx_symbol_1_clk",
			      "ufs_phy_tx_symbol_0_clk",
			      "usb3_phy_wrapper_gcc_usb30_pipe_clk";
		#clock-cells = <1>;
		#reset-cells = <1>;
	};

	gpucc: clock-controller@3d90000 {
		compatible = "qcom,kalama-gpucc", "syscon";
		reg = <0x3d90000 0xa000>;
		reg-name = "cc_base";
		vdd_cx-supply = <&VDD_CX_LEVEL>;
		vdd_mx-supply = <&VDD_MXA_LEVEL>;
		vdd_mxc-supply = <&VDD_MXC_LEVEL>;
		clocks = <&rpmhcc RPMH_CXO_CLK>,
			 <&gcc GCC_GPU_GPLL0_CLK_SRC>,
			 <&gcc GCC_GPU_GPLL0_DIV_CLK_SRC>;
		clock-names = "bi_tcxo",
			      "gpll0_out_main",
			      "gpll0_out_main_div";
		#clock-cells = <1>;
		#reset-cells = <1>;
	};

	tcsrcc: clock-controller@1fc0000 {
		compatible = "qcom,kalama-tcsrcc", "syscon";
		reg = <0x1fc0000 0x30000>;
		reg-name = "cc_base";
		#clock-cells = <1>;
		#reset-cells = <1>;
	};

	videocc: clock-controller@aaf0000 {
		compatible = "qcom,kalama-videocc", "syscon";
		reg = <0xaaf0000 0x10000>;
		reg-name = "cc_base";
		vdd_mm-supply = <&VDD_MM_LEVEL>;
		vdd_mxc-supply = <&VDD_MXC_LEVEL>;
		clocks = <&rpmhcc RPMH_CXO_CLK>,
			 <&rpmhcc RPMH_CXO_CLK_A>,
			 <&sleep_clk>,
			 <&gcc GCC_VIDEO_AHB_CLK>;
		clock-names = "bi_tcxo",
			      "bi_tcxo_ao",
			      "sleep_clk",
			      "iface";
		#clock-cells = <1>;
		#reset-cells = <1>;
	};

	apsscc: syscon@17A80000 {
		compatible = "syscon";
		reg = <0x17A80000 0x21000>;
	};

	mccc: syscon@240ba000 {
		compatible = "syscon";
		reg = <0x240ba000 0x54>;
	};

	debugcc: clock-controller@0 {
		compatible = "qcom,kalama-debugcc";
		qcom,apsscc = <&apsscc>;
		qcom,camcc = <&camcc>;
		qcom,dispcc = <&dispcc>;
		qcom,gcc = <&gcc>;
		qcom,gpucc = <&gpucc>;
		qcom,tcsrcc = <&tcsrcc>;
		qcom,videocc = <&videocc>;
		qcom,mccc = <&mccc>;
		clocks = <&rpmhcc RPMH_CXO_CLK>,
			 <&camcc 0>,
			 <&dispcc 0>,
			 <&gcc 0>,
			 <&gpucc 0>,
			 <&tcsrcc 0>,
			 <&videocc 0>;
		clock-names = "xo_clk_src",
			      "camcc",
			      "dispcc",
			      "gcc",
			      "gpucc",
			      "tcsrcc",
			      "videocc";
		#clock-cells = <1>;
	};

	cpufreq_hw: qcom,cpufreq-hw {
		compatible = "qcom,cpufreq-epss";
		reg = <0x17D91000 0x1000>,
		      <0x17D92000 0x1000>,
		      <0x17D93000 0x1000>;
		reg-names = "freq-domain0",
			    "freq-domain1",
			    "freq-domain2";
		clocks = <&rpmhcc RPMH_CXO_CLK>, <&gcc GCC_GPLL0>;
		clock-names = "xo", "alternate";
		interrupts = <GIC_SPI 30 IRQ_TYPE_LEVEL_HIGH>,
			     <GIC_SPI 31 IRQ_TYPE_LEVEL_HIGH>,
			     <GIC_SPI 19 IRQ_TYPE_LEVEL_HIGH>;
		interrupt-names = "dcvsh0_int",
				  "dcvsh1_int",
				  "dcvsh2_int";
		#freq-domain-cells = <1>;
	};

	qcom,cpufreq-hw-debug {
		compatible = "qcom,cpufreq-hw-epss-debug";
		qcom,freq-hw-domain = <&cpufreq_hw 0>,
				      <&cpufreq_hw 1>,
				      <&cpufreq_hw 2>;
	};

	/* CAM_CC GDSCs */
	cam_cc_bps_gdsc: qcom,gdsc@adf0004 {
		compatible = "qcom,gdsc";
		reg = <0xadf0004 0x4>;
		regulator-name = "cam_cc_bps_gdsc";
		clock-names = "ahb_clk";
		clocks = <&gcc GCC_CAMERA_AHB_CLK>;
		parent-supply = <&VDD_MM_MXC_VOTER_LEVEL>;
		qcom,gds-timeout = <1500>;
		qcom,support-hw-trigger;
		qcom,retain-regs;
		qcom,support-cfg-gdscr;
	};

	cam_cc_ife_0_gdsc: qcom,gdsc@adf1004 {
		compatible = "qcom,gdsc";
		reg = <0xadf1004 0x4>;
		regulator-name = "cam_cc_ife_0_gdsc";
		clock-names = "ahb_clk";
		clocks = <&gcc GCC_CAMERA_AHB_CLK>;
		parent-supply = <&VDD_MM_MXC_VOTER_LEVEL>;
		qcom,gds-timeout = <1500>;
		qcom,retain-regs;
		qcom,support-cfg-gdscr;
	};

	cam_cc_ife_1_gdsc: qcom,gdsc@adf2004 {
		compatible = "qcom,gdsc";
		reg = <0xadf2004 0x4>;
		regulator-name = "cam_cc_ife_1_gdsc";
		clock-names = "ahb_clk";
		clocks = <&gcc GCC_CAMERA_AHB_CLK>;
		parent-supply = <&VDD_MM_MXC_VOTER_LEVEL>;
		qcom,gds-timeout = <1500>;
		qcom,retain-regs;
		qcom,support-cfg-gdscr;
	};

	cam_cc_ife_2_gdsc: qcom,gdsc@adf2294 {
		compatible = "qcom,gdsc";
		reg = <0xadf2294 0x4>;
		regulator-name = "cam_cc_ife_2_gdsc";
		clock-names = "ahb_clk";
		clocks = <&gcc GCC_CAMERA_AHB_CLK>;
		parent-supply = <&VDD_MM_MXC_VOTER_LEVEL>;
		qcom,gds-timeout = <1500>;
		qcom,retain-regs;
		qcom,support-cfg-gdscr;
	};

	cam_cc_ipe_0_gdsc: qcom,gdsc@adf03b8 {
		compatible = "qcom,gdsc";
		reg = <0xadf03b8 0x4>;
		regulator-name = "cam_cc_ipe_0_gdsc";
		clock-names = "ahb_clk";
		clocks = <&gcc GCC_CAMERA_AHB_CLK>;
		parent-supply = <&VDD_MM_MXC_VOTER_LEVEL>;
		qcom,gds-timeout = <1500>;
		qcom,support-hw-trigger;
		qcom,retain-regs;
		qcom,support-cfg-gdscr;
	};

	cam_cc_sbi_gdsc: qcom,gdsc@adf052c {
		compatible = "qcom,gdsc";
		reg = <0xadf052c 0x4>;
		regulator-name = "cam_cc_sbi_gdsc";
		clock-names = "ahb_clk";
		clocks = <&gcc GCC_CAMERA_AHB_CLK>;
		parent-supply = <&VDD_MM_MXC_VOTER_LEVEL>;
		qcom,gds-timeout = <1500>;
		qcom,retain-regs;
		qcom,support-cfg-gdscr;
	};

	cam_cc_sfe_0_gdsc: qcom,gdsc@adf3280 {
		compatible = "qcom,gdsc";
		reg = <0xadf3280 0x4>;
		regulator-name = "cam_cc_sfe_0_gdsc";
		clock-names = "ahb_clk";
		clocks = <&gcc GCC_CAMERA_AHB_CLK>;
		parent-supply = <&VDD_MM_MXC_VOTER_LEVEL>;
		qcom,gds-timeout = <1500>;
		qcom,retain-regs;
		qcom,support-cfg-gdscr;
	};

	cam_cc_sfe_1_gdsc: qcom,gdsc@adf33e0 {
		compatible = "qcom,gdsc";
		reg = <0xadf33e0 0x4>;
		regulator-name = "cam_cc_sfe_1_gdsc";
		clock-names = "ahb_clk";
		clocks = <&gcc GCC_CAMERA_AHB_CLK>;
		parent-supply = <&VDD_MM_MXC_VOTER_LEVEL>;
		qcom,gds-timeout = <1500>;
		qcom,retain-regs;
		qcom,support-cfg-gdscr;
	};

	cam_cc_titan_top_gdsc: qcom,gdsc@adf4058 {
		compatible = "qcom,gdsc";
		reg = <0xadf4058 0x4>;
		regulator-name = "cam_cc_titan_top_gdsc";
		clock-names = "ahb_clk";
		clocks = <&gcc GCC_CAMERA_AHB_CLK>;
		parent-supply = <&VDD_MM_MXC_VOTER_LEVEL>;
		proxy-supply = <&cam_cc_titan_top_gdsc>;
		interconnects = <&mmss_noc MASTER_CAMNOC_HF &mmss_noc SLAVE_MNOC_HF_MEM_NOC>;
		interconnect-names = "mmnoc";
		qcom,gds-timeout = <1500>;
		qcom,proxy-consumer-enable;
		qcom,retain-regs;
		qcom,support-cfg-gdscr;
	};

	/* DISP_CC GDSCs */
	disp_cc_mdss_core_gdsc: qcom,gdsc@af09000 {
		compatible = "qcom,gdsc";
		reg = <0xaf09000 0x4>;
		regulator-name = "disp_cc_mdss_core_gdsc";
		clock-names = "ahb_clk";
		clocks = <&gcc GCC_DISP_AHB_CLK>;
		parent-supply = <&VDD_MM_LEVEL>;
		proxy-supply = <&disp_cc_mdss_core_gdsc>;
		qcom,gds-timeout = <1500>;
		qcom,proxy-consumer-enable;
		qcom,support-hw-trigger;
		qcom,retain-regs;
		qcom,support-cfg-gdscr;
	};

	disp_cc_mdss_core_int2_gdsc: qcom,gdsc@af0b000 {
		compatible = "qcom,gdsc";
		reg = <0xaf0b000 0x4>;
		regulator-name = "disp_cc_mdss_core_int2_gdsc";
		clock-names = "ahb_clk";
		clocks = <&gcc GCC_DISP_AHB_CLK>;
		parent-supply = <&VDD_MM_LEVEL>;
		qcom,gds-timeout = <1500>;
		qcom,support-hw-trigger;
		qcom,retain-regs;
		qcom,support-cfg-gdscr;
	};

	gcc_apcs_gdsc_vote_ctrl: syscon@152020{
		compatible = "syscon";
		reg = <0x152020 0x4>;
	};

	/* GCC GDSCs */
	gcc_pcie_0_gdsc: qcom,gdsc@16b004 {
		compatible = "qcom,gdsc";
		reg = <0x16b004 0x4>;
		regulator-name = "gcc_pcie_0_gdsc";
		parent-supply = <&VDD_CX_LEVEL>;
		clocks = <&gcc 0>;
		qcom,gds-timeout = <1500>;
		qcom,retain-regs;
		qcom,no-status-check-on-disable;
		qcom,collapse-vote = <&gcc_apcs_gdsc_vote_ctrl 0>;
		qcom,support-cfg-gdscr;
	};

	gcc_pcie_0_phy_gdsc: qcom,gdsc@16c000 {
		compatible = "qcom,gdsc";
		reg = <0x16c000 0x4>;
		regulator-name = "gcc_pcie_0_phy_gdsc";
		parent-supply = <&VDD_MXA_LEVEL>;
		clocks = <&gcc 0>;
		qcom,gds-timeout = <1500>;
		qcom,retain-regs;
		qcom,no-status-check-on-disable;
		qcom,collapse-vote = <&gcc_apcs_gdsc_vote_ctrl 3>;
		qcom,support-cfg-gdscr;
	};

	gcc_pcie_1_gdsc: qcom,gdsc@18d004 {
		compatible = "qcom,gdsc";
		reg = <0x18d004 0x4>;
		regulator-name = "gcc_pcie_1_gdsc";
		parent-supply = <&VDD_CX_LEVEL>;
		clocks = <&gcc 0>;
		qcom,gds-timeout = <1500>;
		qcom,retain-regs;
		qcom,no-status-check-on-disable;
		qcom,collapse-vote = <&gcc_apcs_gdsc_vote_ctrl 1>;
		qcom,support-cfg-gdscr;
	};

	gcc_pcie_1_phy_gdsc: qcom,gdsc@18e000 {
		compatible = "qcom,gdsc";
		reg = <0x18e000 0x4>;
		regulator-name = "gcc_pcie_1_phy_gdsc";
		parent-supply = <&VDD_MXA_LEVEL>;
		clocks = <&gcc 0>;
		qcom,gds-timeout = <1500>;
		qcom,retain-regs;
		qcom,no-status-check-on-disable;
		qcom,collapse-vote = <&gcc_apcs_gdsc_vote_ctrl 4>;
		qcom,support-cfg-gdscr;
	};

	gcc_ufs_mem_phy_gdsc: qcom,gdsc@19e000 {
		compatible = "qcom,gdsc";
		reg = <0x19e000 0x4>;
		regulator-name = "gcc_ufs_mem_phy_gdsc";
		clocks = <&gcc 0>;
		qcom,gds-timeout = <1500>;
		parent-supply = <&VDD_MXA_LEVEL>;
		qcom,retain-regs;
		qcom,support-cfg-gdscr;
	};

	gcc_ufs_phy_gdsc: qcom,gdsc@177004 {
		compatible = "qcom,gdsc";
		reg = <0x177004 0x4>;
		regulator-name = "gcc_ufs_phy_gdsc";
		parent-supply = <&VDD_CX_LEVEL>;
		proxy-supply = <&gcc_ufs_phy_gdsc>;
		clocks = <&gcc 0>;
		qcom,gds-timeout = <1500>;
		qcom,proxy-consumer-enable;
		qcom,retain-regs;
		qcom,support-cfg-gdscr;
	};

	gcc_usb30_prim_gdsc: qcom,gdsc@139004 {
		compatible = "qcom,gdsc";
		reg = <0x139004 0x4>;
		regulator-name = "gcc_usb30_prim_gdsc";
		proxy-supply = <&gcc_usb30_prim_gdsc>;
		clocks = <&gcc 0>;
		qcom,gds-timeout = <1500>;
		qcom,proxy-consumer-enable;
		qcom,retain-regs;
		qcom,support-cfg-gdscr;
	};

	gcc_usb3_phy_gdsc: qcom,gdsc@150018 {
		compatible = "qcom,gdsc";
		reg = <0x150018 0x4>;
		regulator-name = "gcc_usb3_phy_gdsc";
		clocks = <&gcc 0>;
		qcom,gds-timeout = <1500>;
		parent-supply = <&VDD_MXA_LEVEL>;
		qcom,proxy-consumer-enable;
		qcom,retain-regs;
		qcom,support-cfg-gdscr;
	};

	/* GPU_CC GDSCs */
	gpu_cc_cx_gdsc_hw_ctrl: syscon@3d9953c {
		compatible = "syscon";
		reg = <0x3d9953c 0x4>;
	};

	gpu_cc_cx_gdsc: qcom,gdsc@3d99108 {
		compatible = "qcom,gdsc";
		reg = <0x3d99108 0x4>;
		regulator-name = "gpu_cc_cx_gdsc";
		parent-supply = <&VDD_CX_LEVEL>;
		hw-ctrl-addr = <&gpu_cc_cx_gdsc_hw_ctrl>;
		qcom,no-status-check-on-disable;
		qcom,clk-dis-wait-val = <8>;
		qcom,gds-timeout = <1500>;
		qcom,retain-regs;
	};

	gpu_cc_gx_domain_addr: syscon@3d99504 {
		compatible = "syscon";
		reg = <0x3d99504 0x4>;
	};

	gpu_cc_gx_sw_reset: syscon@3d99058 {
		compatible = "syscon";
		reg = <0x3d99058 0x4>;
	};

	gpu_cc_gx_acd_reset: syscon@3d99358 {
		compatible = "syscon";
		reg = <0x3d99358 0x4>;
	};

	gpu_cc_gx_acd_iroot_reset: syscon@3d9958c {
		compatible = "syscon";
		reg = <0x3d9958c 0x4>;
	};

	gpu_cc_gx_gdsc: qcom,gdsc@3d9905c {
		compatible = "qcom,gdsc";
		reg = <0x3d9905c 0x4>;
		regulator-name = "gpu_cc_gx_gdsc";
		domain-addr = <&gpu_cc_gx_domain_addr>;
		sw-reset = <&gpu_cc_gx_sw_reset>,
			   <&gpu_cc_gx_acd_reset>,
			   <&gpu_cc_gx_acd_iroot_reset>;
		parent-supply = <&VDD_GFX_MXC_VOTER_LEVEL>;
		qcom,reset-aon-logic;
		qcom,gds-timeout = <1500>;
		qcom,retain-regs;
		qcom,support-cfg-gdscr;
	};

	/* VIDEO_CC GDSCs */
	video_cc_mvs0_gdsc: qcom,gdsc@abf80a4 {
		compatible = "qcom,gdsc";
		reg = <0xabf80a4 0x4>;
		regulator-name = "video_cc_mvs0_gdsc";
		parent-supply = <&video_cc_mvs0c_gdsc>;
		clock-names = "ahb_clk";
		clocks = <&gcc GCC_VIDEO_AHB_CLK>;
		qcom,gds-timeout = <1500>;
		qcom,support-hw-trigger;
		qcom,retain-regs;
		qcom,support-cfg-gdscr;
	};

	video_cc_mvs0c_gdsc: qcom,gdsc@abf804c {
		compatible = "qcom,gdsc";
		reg = <0xabf804c 0x4>;
		regulator-name = "video_cc_mvs0c_gdsc";
		clock-names = "ahb_clk";
		clocks = <&gcc GCC_VIDEO_AHB_CLK>;
		parent-supply = <&VDD_MM_MXC_VOTER_LEVEL>;
		qcom,gds-timeout = <1500>;
		qcom,retain-regs;
		qcom,support-cfg-gdscr;
	};

	video_cc_mvs1_gdsc: qcom,gdsc@abf80cc {
		compatible = "qcom,gdsc";
		reg = <0xabf80cc 0x4>;
		regulator-name = "video_cc_mvs1_gdsc";
		parent-supply = <&video_cc_mvs1c_gdsc>;
		clock-names = "ahb_clk";
		clocks = <&gcc GCC_VIDEO_AHB_CLK>;
		qcom,gds-timeout = <1500>;
		qcom,support-hw-trigger;
		qcom,retain-regs;
		qcom,support-cfg-gdscr;
	};

	video_cc_mvs1c_gdsc: qcom,gdsc@abf8078 {
		compatible = "qcom,gdsc";
		reg = <0xabf8078 0x4>;
		regulator-name = "video_cc_mvs1c_gdsc";
		parent-supply = <&VDD_MM_MXC_VOTER_LEVEL>;
		clock-names = "ahb_clk";
		clocks = <&gcc GCC_VIDEO_AHB_CLK>;
		qcom,gds-timeout = <1500>;
		qcom,retain-regs;
		qcom,support-cfg-gdscr;
	};

	sdhc2_opp_table: sdhc2-opp-table {
		compatible = "operating-points-v2";

		opp-100000000 {
			opp-hz = /bits/ 64 <100000000>;
			opp-peak-kBps = <160000 100000>;
			opp-avg-kBps = <50000 0>;
		};

		opp-202000000 {
			opp-hz = /bits/ 64 <202000000>;
			opp-peak-kBps = <200000 120000>;
			opp-avg-kBps = <104000 0>;
		};
	};

	sdhc_2: sdhci@8804000 {
		status = "disabled";

		compatible = "qcom,sdhci-msm-v5";
		reg = <0x08804000 0x1000>;
		reg-names = "hc_mem";

		interrupts = <GIC_SPI 207 IRQ_TYPE_LEVEL_HIGH>,
				<GIC_SPI 223 IRQ_TYPE_LEVEL_HIGH>;
		interrupt-names = "hc_irq", "pwr_irq";

		bus-width = <4>;
		no-sdio;
		no-mmc;
		qcom,restore-after-cx-collapse;
		qcom,uses_level_shifter;
		qcom,dll_lock_bist_fail_wa;

		clocks = <&gcc GCC_SDCC2_AHB_CLK>,
			<&gcc GCC_SDCC2_APPS_CLK>;
		clock-names = "iface", "core";

		/*
		 * DLL HSR settings. Refer go/hsr - <Target> DLL settings.
		 * Note that the DLL_CONFIG_2 value is not passed from the
		 * device tree, but it is calculated in the driver.
		 */
		qcom,dll-hsr-list = <0x0007442C 0x0 0x10
					0x090106C0 0x80040868>;

		iommus = <&apps_smmu 0x540 0x0>;
		dma-coherent;

		interconnects = <&aggre2_noc MASTER_SDCC_2 &mc_virt SLAVE_EBI1>,
			      <&gem_noc MASTER_APPSS_PROC &config_noc
			      SLAVE_SDCC_2>;
		interconnect-names = "sdhc-ddr","cpu-sdhc";
		operating-points-v2 = <&sdhc2_opp_table>;

		qos0 {
			mask = <0xf0>;
			vote = <44>;
		};

		qos1 {
			mask = <0x0f>;
			vote = <44>;
		};
	};

	ufsphy_mem: ufsphy_mem@1d80000 {
		reg = <0x1d80000 0x1934>;
		reg-names = "phy_mem";
		#phy-cells = <0>;

		lanes-per-direction = <2>;
		clock-names = "ref_clk_src",
			"ref_aux_clk", "qref_clk",
			"rx_sym0_mux_clk", "rx_sym1_mux_clk", "tx_sym0_mux_clk",
			"rx_sym0_phy_clk", "rx_sym1_phy_clk", "tx_sym0_phy_clk";
		clocks = <&rpmhcc RPMH_CXO_PAD_CLK>,
			<&gcc GCC_UFS_PHY_PHY_AUX_CLK>,
			<&tcsrcc TCSR_UFS_CLKREF_EN>,
			<&gcc GCC_UFS_PHY_RX_SYMBOL_0_CLK_SRC>,
			<&gcc GCC_UFS_PHY_RX_SYMBOL_1_CLK_SRC>,
			<&gcc GCC_UFS_PHY_TX_SYMBOL_0_CLK_SRC>,
			<&gcc GCC_UFS_PHY_RX_SYMBOL_0_CLK>,
			<&gcc GCC_UFS_PHY_RX_SYMBOL_1_CLK>,
			<&gcc GCC_UFS_PHY_TX_SYMBOL_0_CLK>;
		resets = <&ufshc_mem 0>;
		status = "disabled";
	};

	ice_cfg: shared_ice {
		 alg1 {
		      alg-name = "alg1";
		      rx-alloc-percent = <60>;
		      status = "disabled";
		 };

		 alg2 {
		      alg-name = "alg2";
		      status = "ok";
		 };

		 alg3 {
		      alg-name = "alg3";
		      num-core = <17 17 10 7>;
		      status = "disabled";
		 };
	};

	ufshc_mem: ufshc@1d84000 {
		compatible = "qcom,ufshc";
		reg = <0x1d84000 0x3000>,
		      <0x1d88000 0x8000>,
		      <0x1d90000 0x9000>;
		reg-names = "ufs_mem", "ufs_ice", "ufs_ice_hwkm";
		interrupts = <GIC_SPI 265 IRQ_TYPE_LEVEL_HIGH>;
		phys = <&ufsphy_mem>;
		phy-names = "ufsphy";
		#reset-cells = <1>;

		qcom,prime-mask = <0x80>;
		qcom,silver-mask = <0x0f>;
		limit-tx-hs-gear=<4>;
		limit-rx-hs-gear=<4>;
		limit-rate=<2>;
		limit-phy-submode=<1>;
		lanes-per-direction = <2>;
		dev-ref-clk-freq = <0>; /* 19.2 MHz */
		clock-names =
			"core_clk",
			"bus_aggr_clk",
			"iface_clk",
			"core_clk_unipro",
			"core_clk_ice",
			"ref_clk",
			"tx_lane0_sync_clk",
			"rx_lane0_sync_clk",
			"rx_lane1_sync_clk";
		clocks =
			<&gcc GCC_UFS_PHY_AXI_CLK>,
			<&gcc GCC_AGGRE_UFS_PHY_AXI_CLK>,
			<&gcc GCC_UFS_PHY_AHB_CLK>,
			<&gcc GCC_UFS_PHY_UNIPRO_CORE_CLK>,
			<&gcc GCC_UFS_PHY_ICE_CORE_CLK>,
			<&rpmhcc RPMH_LN_BB_CLK3>,
			<&gcc GCC_UFS_PHY_TX_SYMBOL_0_CLK>,
			<&gcc GCC_UFS_PHY_RX_SYMBOL_0_CLK>,
			<&gcc GCC_UFS_PHY_RX_SYMBOL_1_CLK>;
		freq-table-hz =
			<75000000 300000000>,
			<0 0>,
			<0 0>,
			<75000000 300000000>,
			<100000000 403000000>,
			<0 0>,
			<0 0>,
			<0 0>,
			<0 0>;

		interconnects = <&aggre1_noc MASTER_UFS_MEM &mc_virt SLAVE_EBI1>,
		      <&gem_noc MASTER_APPSS_PROC &config_noc SLAVE_UFS_MEM_CFG>;
		interconnect-names = "ufs-ddr", "cpu-ufs";

		qcom,ufs-bus-bw,name = "ufshc_mem";
		qcom,ufs-bus-bw,num-cases = <30>;
		qcom,ufs-bus-bw,num-paths = <2>;
		qcom,ufs-bus-bw,vectors-KBps =
		/*
		 * During HS G3 UFS runs at nominal voltage corner, vote
		 * higher bandwidth to push other buses in the data path
		 * to run at nominal to achieve max throughput.
		 * 4GBps pushes BIMC to run at nominal.
		 * 200MBps pushes CNOC to run at nominal.
		 * Vote for half of this bandwidth for HS G3 1-lane.
		 * For max bandwidth, vote high enough to push the buses
		 * to run in turbo voltage corner.
		 */
		<0 0>, <0 0>,          /* No vote */
		<922 0>, <1000 0>,     /* PWM G1 */
		<1844 0>, <1000 0>,    /* PWM G2 */
		<3688 0>, <1000 0>,    /* PWM G3 */
		<7376 0>, <1000 0>,    /* PWM G4 */
		<14752 0>, <1000 0>,   /* PWM G5 */
		<1844 0>, <1000 0>,    /* PWM G1 L2 */
		<3688 0>, <1000 0>,    /* PWM G2 L2 */
		<7376 0>, <1000 0>,    /* PWM G3 L2 */
		<14752 0>, <1000 0>,   /* PWM G4 L2 */
		<29504 0>, <1000 0>,   /* PWM G5 L2 */
		<127796 0>, <1000 0>,  /* HS G1 RA */
		<255591 0>, <1000 0>,  /* HS G2 RA */
		<1492582 0>, <102400 0>,  /* HS G3 RA */
		<2915200 0>, <204800 0>,  /* HS G4 RA */
		<255591 0>, <1000 0>,  /* HS G1 RA L2 */
		<511181 0>, <1000 0>,  /* HS G2 RA L2 */
		<1492582 0>, <204800 0>, /* HS G3 RA L2 */
		<2915200 0>, <409600 0>, /* HS G4 RA L2 */
		<149422 0>, <1000 0>,  /* HS G1 RB */
		<298189 0>, <1000 0>,  /* HS G2 RB */
		<1492582 0>, <102400 0>,  /* HS G3 RB */
		<2915200 0>, <204800 0>,  /* HS G4 RB */
		<298189 0>, <1000 0>,  /* HS G1 RB L2 */
		<596378 0>, <1000 0>,  /* HS G2 RB L2 */
		/* As UFS working in HS G3 RB L2 mode, aggregated
		 * bandwidth (AB) should take care of providing
		 * optimum throughput requested. However, as tested,
		 * in order to scale up CNOC clock, instantaneous
		 * bindwidth (IB) needs to be given a proper value too.
		 */
		<1492582 0>, <204800 409600>, /* HS G3 RB L2 KBPs */
		<2915200 0>, <409600 409600>, /* HS G4 RB L2 */
		<5836800 0>, <819200 0>,      /* HS G5 RA L2*/
		<5836800 0>, <819200 0>,      /* HS G5 RB L2 */
		<7643136 0>, <819200 0>;      /* Max. bandwidth */

		qcom,bus-vector-names = "MIN",
		"PWM_G1_L1", "PWM_G2_L1", "PWM_G3_L1", "PWM_G4_L1", "PWM_G5_L1",
		"PWM_G1_L2", "PWM_G2_L2", "PWM_G3_L2", "PWM_G4_L2", "PWM_G5_L2",
		"HS_RA_G1_L1", "HS_RA_G2_L1", "HS_RA_G3_L1", "HS_RA_G4_L1",
		"HS_RA_G1_L2", "HS_RA_G2_L2", "HS_RA_G3_L2", "HS_RA_G4_L2",
		"HS_RB_G1_L1", "HS_RB_G2_L1", "HS_RB_G3_L1", "HS_RB_G4_L1",
		"HS_RB_G1_L2", "HS_RB_G2_L2", "HS_RB_G3_L2", "HS_RB_G4_L2",
		"HS_RA_G5_L2", "HS_RB_G5_L2",
		"MAX";

		iommus = <&apps_smmu 0x60 0x0>;
		qcom,iommu-dma = "fastmap";
		dma-coherent;

		shared-ice-cfg = <&ice_cfg>;
		qcom,vccq-lpm-uV = <1180000>;

		status = "disabled";
		qos0 {
			mask = <0xf0>;
			vote = <44>;
			perf;
		};

		qos1 {
			mask = <0x0f>;
			vote = <44>;
		};
	};

	tcsr_mutex_block: syscon@1f40000 {
		compatible = "syscon";
		reg = <0x1f40000 0x20000>;
	};

	tcsr_mutex: hwlock {
		compatible = "qcom,tcsr-mutex";
		syscon = <&tcsr_mutex_block 0 0x1000>;
		#hwlock-cells = <1>;
	};

	smem: qcom,smem {
		compatible = "qcom,smem";
		memory-region = <&smem_mem>;
		depends-on-supply = <&tcsr_mutex>;
		hwlocks = <&tcsr_mutex 3>;
	};

	qcom,rmtfs_sharedmem@0 {
		compatible = "qcom,sharedmem-uio";
		reg = <0x0 0x280000>;
		reg-names = "rmtfs";
		qcom,client-id = <0x00000001>;
	};

	aoss_qmp: power-controller@c300000 {
		compatible = "qcom,kalama-aoss-qmp";
		reg = <0xc300000 0x400>;
		interrupt-parent = <&ipcc_mproc>;
		interrupts = <IPCC_CLIENT_AOP
			      IPCC_MPROC_SIGNAL_GLINK_QMP
			      IRQ_TYPE_EDGE_RISING>;
		mboxes = <&ipcc_mproc IPCC_CLIENT_AOP
			  IPCC_MPROC_SIGNAL_GLINK_QMP>;

		#power-domain-cells = <1>;
		#clock-cells = <0>;
	};

	qmp_aop: qcom,qmp-aop {
		compatible = "qcom,qmp-mbox";
		qcom,qmp = <&aoss_qmp>;
		label = "aop";
		#mbox-cells = <1>;
	};

	qmp_tme: qcom,qmp-tme {
		compatible = "qcom,qmp-mbox";
		qcom,remote-pid = <14>;
		mboxes = <&ipcc_mproc IPCC_CLIENT_TME
			  IPCC_MPROC_SIGNAL_GLINK_QMP>;
		mbox-names = "tme_qmp";
		interrupt-parent = <&ipcc_mproc>;
		interrupts = <IPCC_CLIENT_TME
			      IPCC_MPROC_SIGNAL_GLINK_QMP
			      IRQ_TYPE_EDGE_RISING>;

		label = "tme";
		qcom,early-boot;
		priority = <0>;
		mbox-desc-offset = <0x0>;
		#mbox-cells = <1>;
	};

	qcom,tmecom-qmp-client {
		compatible = "qcom,tmecom-qmp-client";
		mboxes = <&qmp_tme 0>;
		mbox-names = "tmecom";
		label = "tmecom";
		depends-on-supply = <&qmp_tme>;
	};

	qcom,smp2p-adsp {
		compatible = "qcom,smp2p";
		qcom,smem = <443>, <429>;
		interrupt-parent = <&ipcc_mproc>;
		interrupts = <IPCC_CLIENT_LPASS IPCC_MPROC_SIGNAL_SMP2P
			      IRQ_TYPE_EDGE_RISING>;
		mboxes = <&ipcc_mproc IPCC_CLIENT_LPASS
			  IPCC_MPROC_SIGNAL_SMP2P>;
		qcom,local-pid = <0>;
		qcom,remote-pid = <2>;

		adsp_smp2p_out: master-kernel {
			qcom,entry-name = "master-kernel";
			#qcom,smem-state-cells = <1>;
		};

		adsp_smp2p_in: slave-kernel {
			qcom,entry-name = "slave-kernel";
			interrupt-controller;
			#interrupt-cells = <2>;
		};

		sleepstate_smp2p_out: sleepstate-out {
			qcom,entry-name = "sleepstate";
			#qcom,smem-state-cells = <1>;
		};

		sleepstate_smp2p_in: qcom,sleepstate-in {
			qcom,entry-name = "sleepstate_see";
			interrupt-controller;
			#interrupt-cells = <2>;
		};

		smp2p_rdbg2_out: qcom,smp2p-rdbg2-out {
			qcom,entry-name = "rdbg";
			#qcom,smem-state-cells = <1>;
		};

		smp2p_rdbg2_in: qcom,smp2p-rdbg2-in {
			qcom,entry-name = "rdbg";
			interrupt-controller;
			#interrupt-cells = <2>;
		};
	};

	qcom,smp2p-cdsp {
		compatible = "qcom,smp2p";
		qcom,smem = <94>, <432>;
		interrupt-parent = <&ipcc_mproc>;
		interrupts = <IPCC_CLIENT_CDSP IPCC_MPROC_SIGNAL_SMP2P
			      IRQ_TYPE_EDGE_RISING>;
		mboxes = <&ipcc_mproc IPCC_CLIENT_CDSP IPCC_MPROC_SIGNAL_SMP2P>;
		qcom,local-pid = <0>;
		qcom,remote-pid = <5>;

		cdsp_smp2p_out: master-kernel {
			qcom,entry-name = "master-kernel";
			#qcom,smem-state-cells = <1>;
		};

		cdsp_smp2p_in: slave-kernel {
			qcom,entry-name = "slave-kernel";
			interrupt-controller;
			#interrupt-cells = <2>;
		};

		smp2p_rdbg5_out: qcom,smp2p-rdbg5-out {
			qcom,entry-name = "rdbg";
			#qcom,smem-state-cells = <1>;
		};

		smp2p_rdbg5_in: qcom,smp2p-rdbg5-in {
			qcom,entry-name = "rdbg";
			interrupt-controller;
			#interrupt-cells = <2>;
		};
	};

	qcom,smp2p-modem {
		compatible = "qcom,smp2p";
		qcom,smem = <435>, <428>;
		interrupt-parent = <&ipcc_mproc>;
		interrupts = <IPCC_CLIENT_MPSS IPCC_MPROC_SIGNAL_SMP2P
			      IRQ_TYPE_EDGE_RISING>;
		mboxes = <&ipcc_mproc IPCC_CLIENT_MPSS IPCC_MPROC_SIGNAL_SMP2P>;
		qcom,local-pid = <0>;
		qcom,remote-pid = <1>;

		modem_smp2p_out: master-kernel {
			qcom,entry-name = "master-kernel";
			#qcom,smem-state-cells = <1>;
		};

		modem_smp2p_in: slave-kernel {
			qcom,entry-name = "slave-kernel";
			interrupt-controller;
			#interrupt-cells = <2>;
		};

		smp2p_ipa_1_out: qcom,smp2p-ipa-1-out {
			qcom,entry-name = "ipa";
			#qcom,smem-state-cells = <1>;
		};

		/* ipa - inbound entry from mss */
		smp2p_ipa_1_in: qcom,smp2p-ipa-1-in {
			qcom,entry-name = "ipa";
			interrupt-controller;
			#interrupt-cells = <2>;
		};
	};

	qcom,smp2p_sleepstate {
		compatible = "qcom,smp2p-sleepstate";
		qcom,smem-states = <&sleepstate_smp2p_out 0>;
		interrupt-parent = <&sleepstate_smp2p_in>;
		interrupts = <0 0>;
		interrupt-names = "smp2p-sleepstate-in";
	};

	qcom,glinkpkt {
		compatible = "qcom,glinkpkt";

		qcom,glinkpkt-at-mdm0 {
			qcom,glinkpkt-edge = "mpss";
			qcom,glinkpkt-ch-name = "DS";
			qcom,glinkpkt-dev-name = "at_mdm0";
		};

		qcom,glinkpkt-apr-apps2 {
			qcom,glinkpkt-edge = "adsp";
			qcom,glinkpkt-ch-name = "apr_apps2";
			qcom,glinkpkt-dev-name = "apr_apps2";
		};

		qcom,glinkpkt-data40-cntl {
			qcom,glinkpkt-edge = "mpss";
			qcom,glinkpkt-ch-name = "DATA40_CNTL";
			qcom,glinkpkt-dev-name = "smdcntl8";
		};

		qcom,glinkpkt-data1 {
			qcom,glinkpkt-edge = "mpss";
			qcom,glinkpkt-ch-name = "DATA1";
			qcom,glinkpkt-dev-name = "smd7";
		};

		qcom,glinkpkt-data4 {
			qcom,glinkpkt-edge = "mpss";
			qcom,glinkpkt-ch-name = "DATA4";
			qcom,glinkpkt-dev-name = "smd8";
		};

		qcom,glinkpkt-data11 {
			qcom,glinkpkt-edge = "mpss";
			qcom,glinkpkt-ch-name = "DATA11";
			qcom,glinkpkt-dev-name = "smd11";
		};
		qcom,glinkpkt-xpan_control {
			qcom,glinkpkt-edge = "adsp";
			qcom,glinkpkt-ch-name = "bt_cp_ctrl";
			qcom,glinkpkt-dev-name = "bt_cp_ctrl";
		};
	};

	qcom,glink {
		compatible = "qcom,glink";
	};

	qcom,qsee_ipc_irq_bridge {
		compatible = "qcom,qsee-ipc-irq-bridge";

		qcom,qsee-ipc-irq-spss {
			qcom,dev-name = "qsee_ipc_irq_spss";
			interrupt-parent = <&ipcc_mproc>;
			interrupts = <IPCC_CLIENT_SPSS
				      IPCC_MPROC_SIGNAL_TZ
				      IRQ_TYPE_EDGE_RISING>;
			label = "spss";
		};
	};

	qrtr-gunyah-tvm {
		compatible = "qcom,qrtr-gunyah";
		qcom,master;
		gunyah-label = <3>;
		peer-name = <2>;
		shared-buffer = <&trust_ui_vm_qrtr>;
	};

	qrtr-gunyah-oemvm {
		compatible = "qcom,qrtr-gunyah";
		qcom,master;
		gunyah-label = <8>;
		peer-name = <4>;
	};

	sys-pm-vx@c320000 {
		compatible = "qcom,sys-pm-violators", "qcom,sys-pm-kalama";
		reg = <0xc320000 0x0400>;
		mboxes = <&qmp_aop 0>;
		mbox-names = "aop";
	};

	soc-sleep-stats@c3f0000 {
		compatible = "qcom,rpmh-sleep-stats";
		reg = <0xc3f0000 0x400>;
		qcom,drv-max = <0x14>;
		ss-name = "modem", "adsp", "adsp_island",
			  "cdsp", "apss";
		mboxes = <&qmp_aop 0>;
		mbox-names = "aop";
		ddr-freq-update;
	};

	cluster-device {
		compatible = "qcom,lpm-cluster-dev";
		power-domains = <&CLUSTER_PD>;
	};

	subsystem-sleep-stats@c3f0000 {
		compatible = "qcom,subsystem-sleep-stats";
		reg = <0xc3f0000 0x400>;
		ddr-freq-update;
	};

	tcsr: syscon@1fc0000 {
	      compatible = "syscon";
	      reg = <0x1fc0000 0x30000>;
	};

	qcom,mpm2-sleep-counter@c221000 {
		compatible = "qcom,mpm2-sleep-counter";
		reg = <0xc221000 0x1000>;
		clock-frequency = <32768>;
	};

	cache-controller@25000000 {
		compatible = "qcom,kalama-llcc", "qcom,llcc-v41";
		reg = <0x25000000 0x800000> , <0x25800000 0x200000>;
		reg-names = "llcc_base", "llcc_broadcast_base";
		interrupts = <GIC_SPI 266 IRQ_TYPE_LEVEL_HIGH>;
		cap-based-alloc-and-pwr-collapse;

		llcc-perfmon {
			compatible = "qcom,llcc-perfmon";
			clocks = <&aoss_qmp QDSS_CLK>;
			clock-names = "qdss_clk";
		};
	};

	qcom,chd {
		compatible = "qcom,core-hang-detect";
		label = "core";
		qcom,threshold-arr = <0x17800058 0x17810058 0x17820058 0x17830058
			0x17840058 0x17850058 0x17860058 0x17870058>;
		qcom,config-arr = <0x17800060 0x17810060 0x17820060 0x17830060
			0x17840060 0x17850060 0x17860060 0x17870060>;
	};

	eud: qcom,msm-eud@88e0000 {
		compatible = "qcom,msm-eud";
		interrupt-names = "eud_irq";
		interrupt-parent = <&pdc>;
		interrupts = <11 IRQ_TYPE_LEVEL_HIGH>;
		reg = <0x088E0000 0x2000>,
			<0x088E2000 0x1000>;
		reg-names = "eud_base", "eud_mode_mgr2";
		qcom,secure-eud-en;
		status = "ok";
	};

	ipcc_mproc: qcom,ipcc@408000 {
		compatible = "qcom,ipcc";
		reg = <0x408000 0x1000>;
		interrupts = <GIC_SPI 229 IRQ_TYPE_LEVEL_HIGH>;
		interrupt-controller;
		#interrupt-cells = <3>;
		#mbox-cells = <2>;
	};

	qcom,msm-cdsp-loader {
		compatible = "qcom,cdsp-loader";
		qcom,proc-img-to-load = "cdsp";
		qcom,rproc-handle = <&cdsp_pas>;
	};

	qcom,msm-adsprpc-mem {
		compatible = "qcom,msm-adsprpc-mem-region";
		memory-region = <&adsp_mem_heap>;
		restrict-access;
	};

	msm_fastrpc: qcom,msm_fastrpc {
		compatible = "qcom,msm-fastrpc-compute";
		qcom,adsp-remoteheap-vmid = <22 37>;
		qcom,fastrpc-adsp-audio-pdr;
		qcom,fastrpc-adsp-sensors-pdr;
		qcom,rpc-latency-us = <235>;
		qcom,fastrpc-gids = <2908>;
		qcom,qos-cores = <0 1 2 3>;

		qcom,msm_fastrpc_compute_cb1 {
			compatible = "qcom,msm-fastrpc-compute-cb";
			label = "cdsprpc-smd";
			iommus = <&apps_smmu 0x1961 0x0000>,
				 <&apps_smmu 0x0C01 0x0020>,
				 <&apps_smmu 0x19C1 0x0010>;
			qcom,iommu-dma-addr-pool = <0x60000000 0x98000000>;
			qcom,iommu-faults = "stall-disable", "HUPCF";
			dma-coherent;
		};

		qcom,msm_fastrpc_compute_cb2 {
			compatible = "qcom,msm-fastrpc-compute-cb";
			label = "cdsprpc-smd";
			iommus = <&apps_smmu 0x1962 0x0000>,
				 <&apps_smmu 0x0C02 0x0020>,
				 <&apps_smmu 0x19C2 0x0010>;
			qcom,iommu-dma-addr-pool = <0x60000000 0x98000000>;
			qcom,iommu-faults = "stall-disable", "HUPCF";
			dma-coherent;
		};

		qcom,msm_fastrpc_compute_cb3 {
			compatible = "qcom,msm-fastrpc-compute-cb";
			label = "cdsprpc-smd";
			iommus = <&apps_smmu 0x1963 0x0000>,
				 <&apps_smmu 0x0C03 0x0020>,
				 <&apps_smmu 0x19C3 0x0010>;
			qcom,iommu-dma-addr-pool = <0x60000000 0x98000000>;
			qcom,iommu-faults = "stall-disable", "HUPCF";
			dma-coherent;
		};

		qcom,msm_fastrpc_compute_cb4 {
			compatible = "qcom,msm-fastrpc-compute-cb";
			label = "cdsprpc-smd";
			iommus = <&apps_smmu 0x1964 0x0000>,
				 <&apps_smmu 0x0C04 0x0020>,
				 <&apps_smmu 0x19C4 0x0010>;
			qcom,iommu-dma-addr-pool = <0x60000000 0x98000000>;
			qcom,iommu-faults = "stall-disable", "HUPCF";
			dma-coherent;
		};

		qcom,msm_fastrpc_compute_cb5 {
			compatible = "qcom,msm-fastrpc-compute-cb";
			label = "cdsprpc-smd";
			iommus = <&apps_smmu 0x1965 0x0000>,
				 <&apps_smmu 0x0C05 0x0020>,
				 <&apps_smmu 0x19C5 0x0010>;
			qcom,iommu-dma-addr-pool = <0x60000000 0x98000000>;
			qcom,iommu-faults = "stall-disable", "HUPCF";
			dma-coherent;
		};

		qcom,msm_fastrpc_compute_cb6 {
			compatible = "qcom,msm-fastrpc-compute-cb";
			label = "cdsprpc-smd";
			iommus = <&apps_smmu 0x1966 0x0000>,
				 <&apps_smmu 0x0C06 0x0020>,
				 <&apps_smmu 0x19C6 0x0010>;
			qcom,iommu-dma-addr-pool = <0x60000000 0x98000000>;
			qcom,iommu-faults = "stall-disable", "HUPCF";
			dma-coherent;
		};

		qcom,msm_fastrpc_compute_cb7 {
			compatible = "qcom,msm-fastrpc-compute-cb";
			label = "cdsprpc-smd";
			iommus = <&apps_smmu 0x1967 0x0000>,
				 <&apps_smmu 0x0C07 0x0020>,
				 <&apps_smmu 0x19C7 0x0010>;
			qcom,iommu-dma-addr-pool = <0x60000000 0x98000000>;
			qcom,iommu-faults = "stall-disable", "HUPCF";
			dma-coherent;
		};

		qcom,msm_fastrpc_compute_cb8 {
			compatible = "qcom,msm-fastrpc-compute-cb";
			label = "cdsprpc-smd";
			iommus = <&apps_smmu 0x1968 0x0000>,
				 <&apps_smmu 0x0C08 0x0020>,
				 <&apps_smmu 0x19C8 0x0010>;
			qcom,iommu-dma-addr-pool = <0x60000000 0x98000000>;
			qcom,iommu-faults = "stall-disable", "HUPCF";
			dma-coherent;
		};

		qcom,msm_fastrpc_compute_cb9 {
			compatible = "qcom,msm-fastrpc-compute-cb";
			label = "cdsprpc-smd";
			qcom,secure-context-bank;
			iommus = <&apps_smmu 0x1969 0x0000>,
				 <&apps_smmu 0x0C09 0x0020>,
				 <&apps_smmu 0x19C9 0x0010>;
			qcom,iommu-dma-addr-pool = <0x40000000 0x98000000>;
			qcom,iommu-faults = "stall-disable", "HUPCF";
			qcom,iommu-vmid = <0xA>;	/* VMID_CP_PIXEL */
			dma-coherent;
		};

		qcom,msm_fastrpc_compute_cb10 {
			compatible = "qcom,msm-fastrpc-compute-cb";
			label = "adsprpc-smd";
			iommus = <&apps_smmu 0x1003 0x0080>,
				 <&apps_smmu 0x1063 0x0000>;
			qcom,iommu-dma-addr-pool = <0x60000000 0x98000000>;
			qcom,iommu-faults = "stall-disable", "HUPCF";
			dma-coherent;
		};

		qcom,msm_fastrpc_compute_cb11 {
			compatible = "qcom,msm-fastrpc-compute-cb";
			label = "adsprpc-smd";
			iommus = <&apps_smmu 0x1004 0x0080>,
				 <&apps_smmu 0x1064 0x0000>;
			qcom,iommu-dma-addr-pool = <0x60000000 0x98000000>;
			qcom,iommu-faults = "stall-disable", "HUPCF";
			dma-coherent;
		};

		qcom,msm_fastrpc_compute_cb12 {
			compatible = "qcom,msm-fastrpc-compute-cb";
			label = "adsprpc-smd";
			iommus = <&apps_smmu 0x1005 0x0080>,
				 <&apps_smmu 0x1065 0x0000>;
			qcom,iommu-dma-addr-pool = <0x60000000 0x98000000>;
			qcom,iommu-faults = "stall-disable", "HUPCF";
			shared-cb = <8>;
			dma-coherent;
		};

		qcom,msm_fastrpc_compute_cb13 {
			compatible = "qcom,msm-fastrpc-compute-cb";
			label = "adsprpc-smd";
			iommus = <&apps_smmu 0x1006 0x0080>,
				 <&apps_smmu 0x1066 0x0000>;
			qcom,iommu-dma-addr-pool = <0x60000000 0x98000000>;
			qcom,iommu-faults = "stall-disable", "HUPCF";
			dma-coherent;
		};

		qcom,msm_fastrpc_compute_cb14 {
			compatible = "qcom,msm-fastrpc-compute-cb";
			label = "adsprpc-smd";
			iommus = <&apps_smmu 0x1007 0x0080>,
				 <&apps_smmu 0x1067 0x0000>;
			qcom,iommu-dma-addr-pool = <0x60000000 0x98000000>;
			qcom,iommu-faults = "stall-disable", "HUPCF";
			dma-coherent;
		};

		qcom,msm_fastrpc_compute_cb15 {
			compatible = "qcom,msm-fastrpc-compute-cb";
			label = "cdsprpc-smd";
			iommus = <&apps_smmu 0x196C 0x0000>,
				 <&apps_smmu 0x0C0C 0x0020>,
				 <&apps_smmu 0x19CC 0x0010>;
			qcom,iommu-dma-addr-pool = <0x60000000 0x98000000>;
			qcom,iommu-faults = "stall-disable", "HUPCF";
			dma-coherent;
		};

		qcom,msm_fastrpc_compute_cb16 {
			compatible = "qcom,msm-fastrpc-compute-cb";
			label = "cdsprpc-smd";
			iommus = <&apps_smmu 0x196D 0x0000>,
				 <&apps_smmu 0x0C0D 0x0020>,
				 <&apps_smmu 0x19CD 0x0010>;
			qcom,iommu-dma-addr-pool = <0x60000000 0x98000000>;
			qcom,iommu-faults = "stall-disable", "HUPCF";
			dma-coherent;
		};

		qcom,msm_fastrpc_compute_cb17 {
			compatible = "qcom,msm-fastrpc-compute-cb";
			label = "cdsprpc-smd";
			iommus = <&apps_smmu 0x196E 0x0000>,
				 <&apps_smmu 0x0C0E 0x0020>,
				 <&apps_smmu 0x19CE 0x0010>;
			qcom,iommu-dma-addr-pool = <0x60000000 0x98000000>;
			qcom,iommu-faults = "stall-disable", "HUPCF";
			dma-coherent;
		};

		qcom,msm_fastrpc_compute_cb18 {
			compatible = "qcom,msm-fastrpc-compute-cb";
			label = "cdsprpc-smd";
			iommus = <&apps_smmu 0x196F 0x0000>,
				 <&apps_smmu 0x0C0F 0x0020>,
				 <&apps_smmu 0x19CF 0x0010>;
			qcom,iommu-dma-addr-pool = <0x60000000 0x98000000>;
			qcom,iommu-faults = "stall-disable", "HUPCF";
			dma-coherent;
		};
	};

	adsp_pas: remoteproc-adsp@03000000 {
		compatible = "qcom,kalama-adsp-pas";
		reg = <0x03000000 0x10000>;
		status = "ok";

		cx-supply = <&VDD_LPI_CX_LEVEL>;
		cx-uV-uA = <RPMH_REGULATOR_LEVEL_TURBO 0>;
		mx-supply = <&VDD_LPI_MX_LEVEL>;
		mx-uV-uA = <RPMH_REGULATOR_LEVEL_TURBO 0>;
		reg-names = "cx", "mx";

		clocks = <&rpmhcc RPMH_CXO_CLK>;
		clock-names = "xo";

		qcom,signal-aop;
		qcom,qmp = <&aoss_qmp>;

		interconnects = <&lpass_lpicx_noc MASTER_LPASS_PROC &mc_virt SLAVE_EBI1>,
				<&aggre2_noc MASTER_CRYPTO &mc_virt SLAVE_EBI1>;
		interconnect-names = "rproc_ddr", "crypto_ddr";

		memory-region = <&adspslpi_mem &q6_adsp_dtb_mem>;

		/* Inputs from ssc */
		interrupts-extended = <&pdc 6 IRQ_TYPE_EDGE_RISING>,
					<&adsp_smp2p_in 0 0>,
					<&adsp_smp2p_in 2 0>,
					<&adsp_smp2p_in 1 0>,
					<&adsp_smp2p_in 3 0>,
					<&adsp_smp2p_in 7 0>;

		interrupt-names = "wdog",
				"fatal",
				"handover",
				"ready",
				"stop-ack",
				"shutdown-ack";

		/* Outputs to turing */
		qcom,smem-states = <&adsp_smp2p_out 0>;
		qcom,smem-state-names = "stop";

		glink_edge: glink-edge {
			qcom,remote-pid = <2>;
			transport = "smem";
			mboxes = <&ipcc_mproc IPCC_CLIENT_LPASS
				  IPCC_MPROC_SIGNAL_GLINK_QMP>;
			mbox-names = "adsp_smem";
			interrupt-parent = <&ipcc_mproc>;
			interrupts = <IPCC_CLIENT_LPASS
				      IPCC_MPROC_SIGNAL_GLINK_QMP
				      IRQ_TYPE_EDGE_RISING>;

			label = "adsp";
			qcom,glink-label = "lpass";

			qcom,adsp_qrtr {
				qcom,glink-channels = "IPCRTR";
				qcom,intents = <0x800  5
						0x2000 3
						0x4400 2>;
				qcom,no-wake-svc = <0x190>;
			};

			qcom,msm_fastrpc_rpmsg {
				compatible = "qcom,msm-fastrpc-rpmsg";
				qcom,glink-channels = "fastrpcglink-apps-dsp";
				qcom,intents = <0x64 64>;
			};

			qcom,msm_adspsleepmon_rpmsg {
				compatible = "qcom,msm-adspsleepmon-rpmsg";
				qcom,glink-channels = "sleepmonglink-apps-adsp";
				qcom,intents = <0x1000 8>;
			};

			qcom,pmic_glink_rpmsg {
				qcom,glink-channels = "PMIC_RTR_ADSP_APPS";
			};

			qcom,pmic_glink_log_rpmsg {
				qcom,glink-channels = "PMIC_LOGS_ADSP_APPS";
				qcom,intents = <0x800 5
						0xc00 3
						0x2000 1>;
			};

		};
	};

	cdsp_pas: remoteproc-cdsp@32300000 {
		compatible = "qcom,kalama-cdsp-pas";
		reg = <0x32300000 0x10000>;
		status = "ok";

		cx-supply = <&VDD_CX_LEVEL>;
		cx-uV-uA = <RPMH_REGULATOR_LEVEL_TURBO 100000>;
		mx-supply = <&VDD_MXC_LEVEL>;
		mx-uV-uA = <RPMH_REGULATOR_LEVEL_TURBO 100000>;
		nsp-supply = <&VDD_NSP_LEVEL>;
		nsp-uV-uA = <RPMH_REGULATOR_LEVEL_TURBO 100000>;
		reg-names = "cx","mx","nsp";

		memory-region = <&cdsp_mem &q6_cdsp_dtb_mem>;

		clocks = <&rpmhcc RPMH_CXO_CLK>;
		clock-names = "xo";

		qcom,signal-aop;
		qcom,qmp = <&aoss_qmp>;

		interconnects = <&nsp_noc MASTER_CDSP_PROC &mc_virt SLAVE_EBI1>,
				<&aggre2_noc MASTER_CRYPTO &mc_virt SLAVE_EBI1>;
		interconnect-names = "rproc_ddr", "crypto_ddr";

		/* Inputs from turing */
		interrupts-extended = <&intc GIC_SPI 578 IRQ_TYPE_EDGE_RISING>,
					<&cdsp_smp2p_in 0 0>,
					<&cdsp_smp2p_in 2 0>,
					<&cdsp_smp2p_in 1 0>,
					<&cdsp_smp2p_in 3 0>,
					<&cdsp_smp2p_in 7 0>;

		interrupt-names = "wdog",
				"fatal",
				"handover",
				"ready",
				"stop-ack",
				"shutdown-ack";

		/* Outputs to turing */
		qcom,smem-states = <&cdsp_smp2p_out 0>;
		qcom,smem-state-names = "stop";

		glink-edge {
			qcom,remote-pid = <5>;
			transport = "smem";
			mboxes = <&ipcc_mproc IPCC_CLIENT_CDSP
				  IPCC_MPROC_SIGNAL_GLINK_QMP>;
			mbox-names = "cdsp_smem";
			interrupt-parent = <&ipcc_mproc>;
			interrupts = <IPCC_CLIENT_CDSP
				      IPCC_MPROC_SIGNAL_GLINK_QMP
				      IRQ_TYPE_EDGE_RISING>;

			label = "cdsp";
			qcom,glink-label = "cdsp";

			qcom,cdsp_qrtr {
				qcom,glink-channels = "IPCRTR";
				qcom,intents = <0x800  5
						0x2000 3
						0x4400 2>;
			};

			qcom,msm_fastrpc_rpmsg {
				compatible = "qcom,msm-fastrpc-rpmsg";
				qcom,glink-channels = "fastrpcglink-apps-dsp";
				qcom,intents = <0x64 64>;
			};

			qcom,msm_cdsprm_rpmsg {
				compatible = "qcom,msm-cdsprm-rpmsg";
				qcom,glink-channels = "cdsprmglink-apps-dsp";
				qcom,intents = <0x20 12>;

				msm_cdsp_rm: qcom,msm_cdsp_rm {
					compatible = "qcom,msm-cdsp-rm";
					qcom,qos-latency-us = <70>;
					qcom,qos-maxhold-ms = <20>;
				};
			};
		};
	};

	modem_pas: remoteproc-mss@04080000 {
		compatible = "qcom,kalama-modem-pas";
		reg = <0x4080000 0x10000>;
		status = "ok";

		clocks = <&rpmhcc RPMH_CXO_CLK>;
		clock-names = "xo";

		cx-supply = <&VDD_CX_LEVEL>;
		cx-uV-uA = <RPMH_REGULATOR_LEVEL_TURBO 100000>;
		mx-supply = <&VDD_MODEM_LEVEL>;
		mx-uV-uA = <RPMH_REGULATOR_LEVEL_NOM_L1 100000>;
		reg-names = "cx", "mx";

		qcom,signal-aop;
		qcom,qmp = <&aoss_qmp>;

		interconnects = <&mc_virt MASTER_LLCC &mc_virt SLAVE_EBI1>,
				<&aggre2_noc MASTER_CRYPTO &mc_virt SLAVE_EBI1>;
		interconnect-names = "rproc_ddr", "crypto_ddr";

		memory-region = <&mpss_mem &q6_mpss_dtb_mem &system_cma>;
		mpss_dsm_mem_reg = <&mpss_dsm_mem>;

		/* Inputs from mss */
		interrupts-extended = <&intc GIC_SPI 264 IRQ_TYPE_EDGE_RISING>,
					<&modem_smp2p_in 0 0>,
					<&modem_smp2p_in 2 0>,
					<&modem_smp2p_in 1 0>,
					<&modem_smp2p_in 3 0>,
					<&modem_smp2p_in 7 0>;

		interrupt-names = "wdog",
				"fatal",
				"handover",
				"ready",
				"stop-ack",
				"shutdown-ack";

		/* Outputs to mss */
		qcom,smem-states = <&modem_smp2p_out 0>;
		qcom,smem-state-names = "stop";

		glink-edge {
			qcom,remote-pid = <1>;
			transport = "smem";
			mboxes = <&ipcc_mproc IPCC_CLIENT_MPSS
				  IPCC_MPROC_SIGNAL_GLINK_QMP>;
			mbox-names = "mpss_smem";
			interrupt-parent = <&ipcc_mproc>;
			interrupts = <IPCC_CLIENT_MPSS
				      IPCC_MPROC_SIGNAL_GLINK_QMP
				      IRQ_TYPE_EDGE_RISING>;

			label = "modem";
			qcom,glink-label = "mpss";

			qcom,modem_qrtr {
				qcom,glink-channels = "IPCRTR";
				qcom,low-latency;
				qcom,intents = <0x800  5
						0x2000 3
						0x4400 2>;
			};

			qcom,modem_ds {
				qcom,glink-channels = "DS";
				qcom,intents = <0x4000 0x2>;
			};
		};
	};

	qcom,guestvm_loader@f3c00000 {
		compatible = "qcom,guestvm-loader";
		qcom,pas-id = <28>;
		qcom,isolate-cpus;
		qcom,vmid = <45>;
		qcom,firmware-name = "trustedvm";
		qcom,reserved-cpus = <0x5>, <0x6>;
		qcom,unisolate-timeout-ms = <12000>;
		memory-region = <&trust_ui_vm_mem>;
	};

	qcom,guestvm_loader@80a00000 {
		compatible = "qcom,guestvm-loader";
		qcom,pas-id = <35>;
		qcom,vmid = <50>;
		qcom,firmware-name = "cpusys_vm";
		memory-region = <&cpusys_vm_mem>;
	};

	tlmm-vm-mem-access {
		compatible = "qcom,tlmm-vm-mem-access";
		qcom,master;
		tlmm-vm-gpio-list = <&tlmm 86 0 &tlmm 87 0 &tlmm 133 0 &tlmm 137 0 &tlmm 44 0 &tlmm 45 0 &tlmm 46 0
					&tlmm 47 0 &tlmm 24 0 &tlmm 25 0 &tlmm 91 0 &tlmm 56 0
					&tlmm 57 0 &tlmm 58 0 &tlmm 59 0 &tlmm 13 0 &tlmm 48 0>;
	};

	tlmm-vm-test {
		compatible = "qcom,tlmm-vm-test";
		qcom,master;
		tlmm-vm-gpio-list = <&tlmm 86 0 &tlmm 87 0 &tlmm 133 0 &tlmm 137 0 &tlmm 44 0 &tlmm 45 0 &tlmm 46 0
				&tlmm 47 0 &tlmm 24 0 &tlmm 25 0 &tlmm 91 0 &tlmm 56 0
				&tlmm 57 0 &tlmm 58 0 &tlmm 59 0 &tlmm 13 0 &tlmm 48 0>;
	};

	trust_ui_vm: qcom,trust_ui_vm@0xf78f8000 {
		reg = <0xf78f8000 0x108000>;
		vm_name = "trustedvm";
		shared-buffers = <&trust_ui_vm_vblk0_ring &trust_ui_vm_vblk1_ring &trust_ui_vm_swiotlb>;
	};

	trust_ui_vm_virt_be0: trust_ui_vm_virt_be0@11 {
		qcom,vm = <&trust_ui_vm>;
		qcom,label = <0x11>;
	};

	trust_ui_vm_virt_be1: trust_ui_vm_virt_be1@10 {
		qcom,vm = <&trust_ui_vm>;
		qcom,label = <0x10>;
	};

	gh-secure-vm-loader@0 {
		compatible = "qcom,gh-secure-vm-loader";
		qcom,pas-id = <28>;
		qcom,vmid = <45>;
		qcom,firmware-name = "trustedvm";
		memory-region = <&trust_ui_vm_mem>;
		virtio-backends = <&trust_ui_vm_virt_be0 &trust_ui_vm_virt_be1>;
	};

	gh-secure-vm-loader@2 {
		compatible = "qcom,gh-secure-vm-loader";
		qcom,pas-id = <35>;
		qcom,vmid = <50>;
		qcom,firmware-name = "cpusys_vm";
		memory-region = <&cpusys_vm_mem>;
	};

	llcc_pmu: llcc-pmu@24095000 {
		compatible = "qcom,llcc-pmu-ver2";
		reg = <0x24095000 0x300>;
		reg-names = "lagg-base";
	};

	qcom_pmu: qcom,pmu {
		compatible = "qcom,pmu";
		qcom,long-counter;
		reg = <0x17d09880 0x380>;
		reg-names = "pmu-base";
		qcom,pmu-events-tbl =
			< 0x0008 0xFF 0x02 0x02 >,
			< 0x0011 0xFF 0x01 0x00 >,
			< 0x0017 0xFF 0xFF 0x04 >,
			< 0x0037 0xFF 0xFF 0x06 >,
			< 0x1000 0xFF 0xFF 0x08 >;
	};

	ddr_freq_table: ddr-freq-table {
		qcom,freq-tbl =
			<  547000 >,
			<  768000 >,
			< 1555000 >,
			< 1708000 >,
			< 2092000 >,
			< 2736000 >,
			< 3187000 >,
			< 3686000 >,
			< 4224000 >;
	};

	llcc_freq_table: llcc-freq-table {
		qcom,freq-tbl =
			<  300000 >,
			<  466000 >,
			<  600000 >,
			<  806000 >,
			<  933000 >,
			< 1066000 >;
	};

	ddrqos_freq_table: ddrqos-freq-table {
		qcom,freq-tbl =
			< 0 >,
			< 1 >;
	};

	qcom_dcvs: qcom,dcvs {
		compatible = "qcom,dcvs";
		#address-cells = <1>;
		#size-cells = <1>;
		ranges;

		qcom_l3_dcvs_hw: l3 {
			compatible = "qcom,dcvs-hw";
			qcom,dcvs-hw-type = <2>;
			qcom,bus-width = <32>;
			reg = <0x17d90000 0x4000>, <0x17d90100 0xa0>;
			reg-names = "l3-base", "l3tbl-base";

			l3_dcvs_sp: sp {
				compatible = "qcom,dcvs-path";
				qcom,dcvs-path-type = <0>;
				qcom,shared-offset = <0x0090>;
			};
		};

		qcom_ddr_dcvs_hw: ddr {
			compatible = "qcom,dcvs-hw";
			qcom,dcvs-hw-type = <0>;
			qcom,bus-width = <4>;
			qcom,freq-tbl = <&ddr_freq_table>;

			ddr_dcvs_sp: sp {
				compatible = "qcom,dcvs-path";
				qcom,dcvs-path-type = <0>;
				interconnects = <&mc_virt MASTER_LLCC
						 &mc_virt SLAVE_EBI1>;
			};

			ddr_dcvs_fp: fp {
				compatible = "qcom,dcvs-path";
				qcom,dcvs-path-type = <1>;
				qcom,fp-voter = <&dcvs_fp>;
			};
		};

		qcom_llcc_dcvs_hw: llcc {
			compatible = "qcom,dcvs-hw";
			qcom,dcvs-hw-type = <1>;
			qcom,bus-width = <16>;
			qcom,freq-tbl = <&llcc_freq_table>;

			llcc_dcvs_sp: sp {
				compatible = "qcom,dcvs-path";
				qcom,dcvs-path-type = <0>;
				interconnects = <&gem_noc MASTER_APPSS_PROC
						 &gem_noc SLAVE_LLCC>;
			};

			llcc_dcvs_fp: fp {
				compatible = "qcom,dcvs-path";
				qcom,dcvs-path-type = <1>;
				qcom,fp-voter = <&dcvs_fp>;
			};
		};

		qcom_ddrqos_dcvs_hw: ddrqos {
			compatible = "qcom,dcvs-hw";
			qcom,dcvs-hw-type = <3>;
			qcom,bus-width = <1>;
			qcom,freq-tbl = <&ddrqos_freq_table>;

			ddrqos_dcvs_sp: sp {
				compatible = "qcom,dcvs-path";
				qcom,dcvs-path-type = <0>;
				interconnects = <&mc_virt MASTER_LLCC
						 &mc_virt SLAVE_EBI1>;
			};
		};
	};

	qcom_memlat: qcom,memlat {
		compatible = "qcom,memlat";

		ddr {
			compatible = "qcom,memlat-grp";
			qcom,target-dev = <&qcom_ddr_dcvs_hw>;
			qcom,sampling-path = <&ddr_dcvs_fp>;
			qcom,miss-ev = <0x1000>;

			silver {
				compatible = "qcom,memlat-mon";
				qcom,cpulist = <&CPU0 &CPU1 &CPU2>;
				qcom,cpufreq-memfreq-tbl =
					< 1113600  547000 >,
					< 1516800  768000 >,
					< 1824000 1555000 >;
				qcom,sampling-enabled;
			};

			gold {
				compatible = "qcom,memlat-mon";
				qcom,cpulist = <&CPU3 &CPU4 &CPU5 &CPU6>;
				qcom,cpufreq-memfreq-tbl =
					<  883200  547000 >,
					< 1113600  768000 >,
					< 1344000 1555000 >,
					< 1881600 2092000 >,
					< 2476800 3187000 >,
					< 2707200 4224000 >;
				qcom,sampling-enabled;
			};

			prime {
				compatible = "qcom,memlat-mon";
				qcom,cpulist = <&CPU7>;
				qcom,cpufreq-memfreq-tbl =
					<  883200  547000 >,
					< 1113600  768000 >,
					< 1344000 1555000 >,
					< 1881600 2092000 >,
					< 2476800 3187000 >,
					< 2707200 4224000 >;
				qcom,sampling-enabled;
			};

			gold-compute {
				compatible = "qcom,memlat-mon";
				qcom,cpulist = <&CPU3 &CPU4 &CPU5 &CPU6 &CPU7>;
				qcom,cpufreq-memfreq-tbl =
					< 1881600  547000 >,
					< 2707200 1555000 >;
				qcom,sampling-enabled;
				qcom,compute-mon;
			};

			prime-latfloor {
				compatible = "qcom,memlat-mon";
				qcom,cpulist = <&CPU7>;
				qcom,cpufreq-memfreq-tbl =
					< 2476800  547000 >,
					< 2707200 4224000 >;
				qcom,sampling-enabled;
			};
		};

		llcc {
			compatible = "qcom,memlat-grp";
			qcom,target-dev = <&qcom_llcc_dcvs_hw>;
			qcom,sampling-path = <&llcc_dcvs_fp>;
			qcom,miss-ev = <0x37>;

			silver {
				compatible = "qcom,memlat-mon";
				qcom,cpulist = <&CPU0 &CPU1 &CPU2>;
				qcom,cpufreq-memfreq-tbl =
					<  614400  300000 >,
					< 1516800  466000 >,
					< 1824000  600000 >;
				qcom,sampling-enabled;
			};

			gold {
				compatible = "qcom,memlat-mon";
				qcom,cpulist = <&CPU3 &CPU4 &CPU5 &CPU6 &CPU7>;
				qcom,cpufreq-memfreq-tbl =
					<  652800  300000 >,
					< 1113600  466000 >,
					< 1344000  600000 >,
					< 1881600  806000 >,
					< 2476800  933000 >,
					< 2707200 1066000 >;
				qcom,sampling-enabled;
			};

			gold-compute {
				compatible = "qcom,memlat-mon";
				qcom,cpulist = <&CPU3 &CPU4 &CPU5 &CPU6 &CPU7>;
				qcom,cpufreq-memfreq-tbl =
					< 1881600  300000 >,
					< 2707200  600000 >;
				qcom,sampling-enabled;
				qcom,compute-mon;
			};
		};

		l3 {
			compatible = "qcom,memlat-grp";
			qcom,target-dev = <&qcom_l3_dcvs_hw>;
			qcom,sampling-path = <&l3_dcvs_sp>;
			qcom,miss-ev = <0x17>;

			silver {
				compatible = "qcom,memlat-mon";
				qcom,cpulist = <&CPU0 &CPU1 &CPU2>;
				qcom,cpufreq-memfreq-tbl =
					<  307200  307200 >,
					<  403200  403200 >,
					<  614400  614400 >,
					<  729400  710400 >,
					<  825600  806400 >,
					<  921600  902400 >,
					< 1113600  998400 >,
					< 1228800 1113600 >,
					< 1324800 1228800 >,
					< 1516800 1420800 >,
					< 1632000 1536000 >,
					< 1824000 1651200 >;
				qcom,sampling-enabled;
			};

			gold {
				compatible = "qcom,memlat-mon";
				qcom,cpulist = <&CPU3 &CPU4 &CPU5 &CPU6>;
				qcom,cpufreq-memfreq-tbl =
					<  307200  307200 >,
					<  537600  614400 >,
					<  883200  710400 >,
					< 1136000  902400 >,
					< 1344000  998400 >,
					< 1555200 1228800 >,
					< 1996800 1420800 >,
					< 2342400 1536000 >,
					< 2707200 1651200 >;
				qcom,sampling-enabled;
			};

			prime {
				compatible = "qcom,memlat-mon";
				qcom,cpulist = <&CPU7>;
				qcom,cpufreq-memfreq-tbl =
					<  307200  307200 >,
					<  537600  614400 >,
					<  883200  710400 >,
					< 1136000  902400 >,
					< 1344000  998400 >,
					< 1555200 1228800 >,
					< 1996800 1420800 >,
					< 2342400 1536000 >,
					< 2707200 1651200 >;
				qcom,sampling-enabled;
			};

			prime-compute {
				compatible = "qcom,memlat-mon";
				qcom,cpulist = <&CPU7>;
				qcom,cpufreq-memfreq-tbl =
					< 1996800  307200 >,
					< 2707200 1651200 >;
				qcom,sampling-enabled;
				qcom,compute-mon;
			};
		};

		ddrqos {
			compatible = "qcom,memlat-grp";
			qcom,target-dev = <&qcom_ddrqos_dcvs_hw>;
			qcom,sampling-path = <&ddrqos_dcvs_sp>;
			qcom,miss-ev = <0x1000>;

			ddrqos_gold_lat: gold {
				compatible = "qcom,memlat-mon";
				qcom,cpulist = <&CPU3 &CPU4 &CPU5 &CPU6 &CPU7>;
				qcom,cpufreq-memfreq-tbl =
					< 1881600 0 >,
					< 2707200 1 >;
				qcom,sampling-enabled;
			};

			ddrqos_prime_lat: prime {
				compatible = "qcom,memlat-mon";
				qcom,cpulist = <&CPU7>;
				qcom,cpufreq-memfreq-tbl =
					< 1401600 0 >,
					< 2707200 1 >;
				qcom,sampling-enabled;
			};

			ddrqos_prime_latfloor: prime-latfloor {
				compatible = "qcom,memlat-mon";
				qcom,cpulist = <&CPU7>;
				qcom,cpufreq-memfreq-tbl =
					< 1996800 0 >,
					< 2707200 1 >;
				qcom,sampling-enabled;
			};
		};
	};

	bwmon_llcc: qcom,bwmon-llcc@240B6300 {
		compatible = "qcom,bwmon4";
		reg = <0x240B6400 0x300>, <0x240B6300 0x200>;
		reg-names = "base", "global_base";
		interrupts = <GIC_SPI 581 IRQ_TYPE_LEVEL_HIGH>;
		qcom,mport = <0>;
		qcom,hw-timer-hz = <19200000>;
		qcom,count-unit = <0x10000>;
		qcom,target-dev = <&qcom_llcc_dcvs_hw>;
	};

	bwmon_ddr: qcom,bwmon-ddr@24091000 {
		compatible = "qcom,bwmon5";
		reg = <0x24091000 0x1000>;
		reg-names = "base";
		interrupts = <GIC_SPI 81 IRQ_TYPE_LEVEL_HIGH>;
		qcom,hw-timer-hz = <19200000>;
		qcom,count-unit = <0x10000>;
		qcom,target-dev = <&qcom_ddr_dcvs_hw>;
	};

	thermal_zones: thermal-zones {
	};

	qcom,qbt_handler {
		compatible = "qcom,qbt-handler";
		qcom,ipc-gpio = <&tlmm 40 0>;
		qcom,finger-detect-gpio = <&tlmm 41 0>;
		qcom,intr2-gpio = <&tlmm 42 0>;
	};

	spmi_bus: spmi0_bus: qcom,spmi@c42d000 {
		compatible = "qcom,spmi-pmic-arb";
		reg = <0xc42d000 0x4000>,
		      <0xc400000 0x3000>,
		      <0xc500000 0x400000>,
		      <0xc440000 0x80000>,
		      <0xc4c0000 0x10000>;
		reg-names = "cnfg", "core", "chnls", "obsrvr", "intr";
		interrupts-extended = <&pdc 1 IRQ_TYPE_LEVEL_HIGH>;
		interrupt-names = "periph_irq";
		interrupt-controller;
		#interrupt-cells = <4>;
		#address-cells = <2>;
		#size-cells = <0>;
		cell-index = <0>;
		qcom,channel = <0>;
		qcom,ee = <0>;
		qcom,bus-id = <0>;
	};

	spmi1_bus: qcom,spmi@c432000 {
		compatible = "qcom,spmi-pmic-arb";
		reg = <0xc432000 0x4000>,
		      <0xc400000 0x3000>,
		      <0xc500000 0x400000>,
		      <0xc440000 0x80000>,
		      <0xc4d0000 0x10000>;
		reg-names = "cnfg", "core", "chnls", "obsrvr", "intr";
		interrupts-extended = <&pdc 3 IRQ_TYPE_LEVEL_HIGH>;
		interrupt-names = "periph_irq";
		interrupt-controller;
		#interrupt-cells = <4>;
		#address-cells = <2>;
		#size-cells = <0>;
		cell-index = <0>;
		qcom,channel = <0>;
		qcom,ee = <0>;
		qcom,bus-id = <1>;
		depends-on-supply = <&spmi0_bus>;
	};

	spmi0_debug_bus: qcom,spmi-debug@10b14000 {
		compatible = "qcom,spmi-pmic-arb-debug";
		reg = <0x10b14000 0x60>, <0x221c8784 0x4>;
		reg-names = "core", "fuse";
		clocks = <&aoss_qmp>;
		clock-names = "core_clk";
		qcom,fuse-enable-bit = <18>;
		#address-cells = <2>;
		#size-cells = <0>;
		depends-on-supply = <&spmi1_bus>;
		depends-on2-supply = <&smb1394_glink_debug>;

		qcom,pmk8550-debug@0 {
			compatible = "qcom,spmi-pmic";
			reg = <0x0 SPMI_USID>;
			#address-cells = <2>;
			#size-cells = <0>;
			qcom,can-sleep;
		};

		qcom,pm8550-debug@1 {
			compatible = "qcom,spmi-pmic";
			reg = <0x1 SPMI_USID>;
			#address-cells = <2>;
			#size-cells = <0>;
			qcom,can-sleep;
		};

		qcom,pm8550vs-debug@2 {
			compatible = "qcom,spmi-pmic";
			reg = <0x2 SPMI_USID>;
			#address-cells = <2>;
			#size-cells = <0>;
			qcom,can-sleep;
		};

		qcom,pm8550vs-debug@3 {
			compatible = "qcom,spmi-pmic";
			reg = <0x3 SPMI_USID>;
			#address-cells = <2>;
			#size-cells = <0>;
			qcom,can-sleep;
		};

		qcom,pm8550vs-debug@4 {
			compatible = "qcom,spmi-pmic";
			reg = <0x4 SPMI_USID>;
			#address-cells = <2>;
			#size-cells = <0>;
			qcom,can-sleep;
		};

		qcom,pm8550ve-debug@5 {
			compatible = "qcom,spmi-pmic";
			reg = <0x5 SPMI_USID>;
			#address-cells = <2>;
			#size-cells = <0>;
			qcom,can-sleep;
		};

		qcom,pm8550vs-debug@6 {
			compatible = "qcom,spmi-pmic";
			reg = <0x6 SPMI_USID>;
			#address-cells = <2>;
			#size-cells = <0>;
			qcom,can-sleep;
		};

		qcom,pm8550b-debug@7 {
			compatible = "qcom,spmi-pmic";
			reg = <0x7 SPMI_USID>;
			#address-cells = <2>;
			#size-cells = <0>;
			qcom,can-sleep;
		};

		qcom,pmr735d-debug@a {
			compatible = "qcom,spmi-pmic";
			reg = <0xa SPMI_USID>;
			#address-cells = <2>;
			#size-cells = <0>;
			qcom,can-sleep;
		};

		qcom,pmr735d-debug@b {
			compatible = "qcom,spmi-pmic";
			reg = <0xb SPMI_USID>;
			#address-cells = <2>;
			#size-cells = <0>;
			qcom,can-sleep;
		};

		qcom,pm8010-debug@c {
			compatible = "qcom,spmi-pmic";
			reg = <0xc SPMI_USID>;
			#address-cells = <2>;
			#size-cells = <0>;
			qcom,can-sleep;
		};

		qcom,pm8010-debug@d {
			compatible = "qcom,spmi-pmic";
			reg = <0xd SPMI_USID>;
			#address-cells = <2>;
			#size-cells = <0>;
			qcom,can-sleep;
		};
	};

	qcom,test-dbl {
		compatible = "qcom,gh-dbl";
		qcom,label = <0x4>;
	};

	qcom,gh-qtimer@17425000 {
		compatible = "qcom,gh-qtmr";
		reg = <0x17425000 0x1000>;
		reg-names = "qtmr-base";
		interrupts = <GIC_SPI 10 IRQ_TYPE_LEVEL_HIGH>;
		interrupt-names = "qcom,qtmr-intr";
		qcom,primary;
	};

	qcom,test-msgq {
		compatible = "qcom,gh-msgq-test";
		gunyah-label = <4>;
		qcom,primary;
	};

	pmic_glink: qcom,pmic_glink {
		compatible = "qcom,pmic-glink";
		qcom,pmic-glink-channel = "PMIC_RTR_ADSP_APPS";
		qcom,subsys-name = "lpass";
		qcom,protection-domain = "tms/servreg", "msm/adsp/charger_pd";
		depends-on-supply = <&ipcc_mproc>;

		battery_charger: qcom,battery_charger {
			compatible = "qcom,battery-charger";
		};

		ucsi: qcom,ucsi {
			compatible = "qcom,ucsi-glink";
		};

		altmode: qcom,altmode {
			compatible = "qcom,altmode-glink";
			#altmode-cells = <1>;
		};
	};

	pmic_glink_log: qcom,pmic_glink_log {
		compatible = "qcom,pmic-glink";
		qcom,pmic-glink-channel = "PMIC_LOGS_ADSP_APPS";

		qcom,battery_debug {
			compatible = "qcom,battery-debug";
		};

		qcom,charger_ulog_glink {
			compatible = "qcom,charger-ulog-glink";
		};

		qcom,spmi_glink_debug {
			compatible = "qcom,spmi-glink-debug";
			#address-cells = <1>;
			#size-cells = <0>;
			depends-on-supply = <&spmi1_bus>;

			/* Primary SPMI bus */
			spmi@0 {
				reg = <0>;
				#address-cells = <2>;
				#size-cells = <0>;

				qcom,pm8550b-debug@7 {
					compatible = "qcom,spmi-pmic";
					reg = <0x7 SPMI_USID>;
					qcom,can-sleep;
				};
			};

			/* Secondary SPMI bus */
			spmi@1 {
				reg = <1>;
				#address-cells = <2>;
				#size-cells = <0>;

				smb1394_glink_debug: qcom,smb1394-debug@9 {
					compatible = "qcom,spmi-pmic";
					reg = <0x9 SPMI_USID>;
					qcom,can-sleep;
				};

				qcom,smb1394-debug@b {
					compatible = "qcom,spmi-pmic";
					reg = <0xb SPMI_USID>;
					qcom,can-sleep;
				};

				qcom,smb1398-debug@d {
					compatible = "qcom,spmi-pmic";
					reg = <0xd SPMI_USID>;
					qcom,can-sleep;
				};
			};
		};
	};

	msm_gpu: qcom,kgsl-3d0@3d00000 { };

	google,debug-kinfo {
		compatible = "google,debug-kinfo";
		memory-region = <&kinfo_mem>;
	};
};

&firmware {
	qcom_scm {
		compatible = "qcom,scm";
		qcom,dload-mode = <&tcsr 0x19000>;
	};

	android {
		compatible = "android,firmware";
		vbmeta {
			compatible = "android,vbmeta";
			parts = "vbmeta,boot,system,vendor,dtbo,recovery";
		};

		fstab {
			compatible = "android,fstab";
			vendor {
				compatible = "android,vendor";
				dev = "/dev/block/platform/soc/1d84000.ufshc/by-name/vendor";
				type = "ext4";
				mnt_flags = "ro,barrier=1,discard";
				fsmgr_flags = "wait,slotselect,avb";
				status = "ok";
			};
		};
	};

	qcom_smcinvoke {
		compatible = "qcom,smcinvoke";
	};

	qtee_shmbridge {
		compatible = "qcom,tee-shared-memory-bridge";
	};
};

#include "ipcc-test.dtsi"
#include "kalama-pinctrl.dtsi"
#include "msm-arm-smmu-kalama.dtsi"
#include "kalama-coresight.dtsi"
#include "kalama-debug.dtsi"
#include "kalama-dma-heaps.dtsi"
#include "kalama-regulators.dtsi"
#include "kalama-qupv3.dtsi"
#include "kalama-usb.dtsi"
#include "kalama-eva.dtsi"
#include "kalama-pcie.dtsi"
#include "msm-rdbg.dtsi"
#include "kalama-thermal.dtsi"
#include "kalama-yodo-thermal.dtsi"

&qupv3_se7_2uart {
	status = "ok";
};

&qupv3_hub_i2c2 {
	status = "ok";
	fsa4480: fsa4480@42 {
		compatible = "qcom,fsa4480-i2c";
		reg = <0x42>;
	};
};
